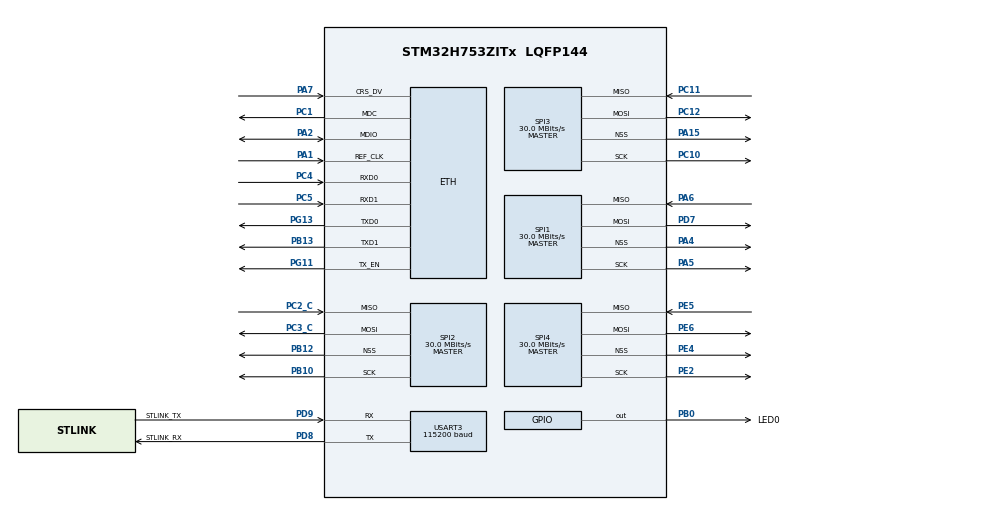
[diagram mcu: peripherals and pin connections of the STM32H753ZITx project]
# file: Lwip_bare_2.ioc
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CORTEX_M7.AccessPermission_S-Cortex_Memory_Protection_Unit_Region1_Settings_S=MPU_REGION_FULL_ACCESS
CORTEX_M7.AccessPermission_S-Cortex_Memory_Protection_Unit_Region2_Settings_S=MPU_REGION_FULL_ACCESS
CORTEX_M7.AccessPermission_Spec=MPU_REGION_NO_ACCESS
CORTEX_M7.BaseAddress_S-Cortex_Memory_Protection_Unit_Region1_Settings_S=0x30020000
CORTEX_M7.BaseAddress_S-Cortex_Memory_Protection_Unit_Region2_Settings_S=0x30040000
CORTEX_M7.BaseAddress_Spec=0x0
CORTEX_M7.CPU_DCache=Enabled
CORTEX_M7.CPU_ICache=Enabled
CORTEX_M7.DisableExec_S-Cortex_Memory_Protection_Unit_Region1_Settings_S=MPU_INSTRUCTION_ACCESS_DISABLE
CORTEX_M7.DisableExec_S-Cortex_Memory_Protection_Unit_Region2_Settings_S=MPU_INSTRUCTION_ACCESS_DISABLE
CORTEX_M7.DisableExec_Spec=MPU_INSTRUCTION_ACCESS_DISABLE
CORTEX_M7.Enable_S-Cortex_Memory_Protection_Unit_Region10_Settings_S=__NULL
CORTEX_M7.Enable_S-Cortex_Memory_Protection_Unit_Region11_Settings_S=__NULL
CORTEX_M7.Enable_S-Cortex_Memory_Protection_Unit_Region12_Settings_S=__NULL
CORTEX_M7.Enable_S-Cortex_Memory_Protection_Unit_Region13_Settings_S=__NULL
CORTEX_M7.Enable_S-Cortex_Memory_Protection_Unit_Region14_Settings_S=__NULL
CORTEX_M7.Enable_S-Cortex_Memory_Protection_Unit_Region15_Settings_S=__NULL
CORTEX_M7.Enable_S-Cortex_Memory_Protection_Unit_Region1_Settings_S=MPU_REGION_ENABLE
CORTEX_M7.Enable_S-Cortex_Memory_Protection_Unit_Region2_Settings_S=MPU_REGION_ENABLE
CORTEX_M7.Enable_S-Cortex_Memory_Protection_Unit_Region3_Settings_S=__NULL
CORTEX_M7.Enable_S-Cortex_Memory_Protection_Unit_Region4_Settings_S=__NULL
CORTEX_M7.Enable_S-Cortex_Memory_Protection_Unit_Region5_Settings_S=__NULL
CORTEX_M7.Enable_S-Cortex_Memory_Protection_Unit_Region6_Settings_S=__NULL
CORTEX_M7.Enable_S-Cortex_Memory_Protection_Unit_Region7_Settings_S=__NULL
CORTEX_M7.Enable_S-Cortex_Memory_Protection_Unit_Region8_Settings_S=__NULL
CORTEX_M7.Enable_S-Cortex_Memory_Protection_Unit_Region9_Settings_S=__NULL
CORTEX_M7.Enable_Spec=MPU_REGION_ENABLE
CORTEX_M7.IsBufferable_S-Cortex_Memory_Protection_Unit_Region1_Settings_S=MPU_ACCESS_NOT_BUFFERABLE
CORTEX_M7.IsBufferable_S-Cortex_Memory_Protection_Unit_Region2_Settings_S=MPU_ACCESS_BUFFERABLE
CORTEX_M7.IsBufferable_Spec=MPU_ACCESS_NOT_BUFFERABLE
CORTEX_M7.IsCacheable_S-Cortex_Memory_Protection_Unit_Region1_Settings_S=MPU_ACCESS_NOT_CACHEABLE
CORTEX_M7.IsCacheable_S-Cortex_Memory_Protection_Unit_Region2_Settings_S=MPU_ACCESS_NOT_CACHEABLE
CORTEX_M7.IsCacheable_Spec=MPU_ACCESS_NOT_CACHEABLE
CORTEX_M7.IsShareable_S-Cortex_Memory_Protection_Unit_Region1_Settings_S=MPU_ACCESS_NOT_SHAREABLE
CORTEX_M7.IsShareable_S-Cortex_Memory_Protection_Unit_Region2_Settings_S=MPU_ACCESS_SHAREABLE
CORTEX_M7.IsShareable_Spec=MPU_ACCESS_SHAREABLE
CORTEX_M7.MPU_Control=MPU_PRIVILEGED_DEFAULT
CORTEX_M7.Size_S-Cortex_Memory_Protection_Unit_Region1_Settings_S=MPU_REGION_SIZE_128KB
CORTEX_M7.Size_S-Cortex_Memory_Protection_Unit_Region2_Settings_S=MPU_REGION_SIZE_512B
CORTEX_M7.Size_Spec=MPU_REGION_SIZE_4GB
CORTEX_M7.SubRegionDisable_S-Cortex_Memory_Protection_Unit_Region1_Settings_S=0x0
CORTEX_M7.SubRegionDisable_S-Cortex_Memory_Protection_Unit_Region2_Settings_S=0x0
CORTEX_M7.SubRegionDisable_Spec=0x87
CORTEX_M7.TypeExtField_S-Cortex_Memory_Protection_Unit_Region1_Settings_S=MPU_TEX_LEVEL1
CORTEX_M7.TypeExtField_S-Cortex_Memory_Protection_Unit_Region2_Settings_S=MPU_TEX_LEVEL0
CORTEX_M7.TypeExtField_Spec=MPU_TEX_LEVEL0
CORTEX_M7.default_mode_Activation=1
Dma.Request0=SPI1_TX
Dma.Request1=SPI1_RX
Dma.Request2=SPI2_TX
Dma.Request3=SPI2_RX
Dma.Request4=SPI3_TX
Dma.Request5=SPI3_RX
Dma.Request6=SPI4_TX
Dma.Request7=SPI4_RX
Dma.SPI1_RX.1.Direction=DMA_PERIPH_TO_MEMORY
Dma.SPI1_RX.1.EventEnable=DISABLE
Dma.SPI1_RX.1.FIFOMode=DMA_FIFOMODE_ENABLE
Dma.SPI1_RX.1.FIFOThreshold=DMA_FIFO_THRESHOLD_FULL
Dma.SPI1_RX.1.Instance=DMA1_Stream1
Dma.SPI1_RX.1.MemBurst=DMA_MBURST_SINGLE
Dma.SPI1_RX.1.MemDataAlignment=DMA_MDATAALIGN_HALFWORD
Dma.SPI1_RX.1.MemInc=DMA_MINC_ENABLE
Dma.SPI1_RX.1.Mode=DMA_NORMAL
Dma.SPI1_RX.1.PeriphBurst=DMA_PBURST_SINGLE
Dma.SPI1_RX.1.PeriphDataAlignment=DMA_PDATAALIGN_HALFWORD
Dma.SPI1_RX.1.PeriphInc=DMA_PINC_DISABLE
Dma.SPI1_RX.1.Polarity=HAL_DMAMUX_REQ_GEN_RISING
Dma.SPI1_RX.1.Priority=DMA_PRIORITY_MEDIUM
Dma.SPI1_RX.1.RequestNumber=1
Dma.SPI1_RX.1.SignalID=NONE
Dma.SPI1_RX.1.SyncEnable=DISABLE
Dma.SPI1_RX.1.SyncPolarity=HAL_DMAMUX_SYNC_NO_EVENT
Dma.SPI1_RX.1.SyncRequestNumber=1
Dma.SPI1_RX.1.SyncSignalID=NONE
Dma.SPI1_TX.0.Direction=DMA_MEMORY_TO_PERIPH
Dma.SPI1_TX.0.EventEnable=DISABLE
Dma.SPI1_TX.0.FIFOMode=DMA_FIFOMODE_ENABLE
Dma.SPI1_TX.0.FIFOThreshold=DMA_FIFO_THRESHOLD_HALFFULL
Dma.SPI1_TX.0.Instance=DMA1_Stream0
Dma.SPI1_TX.0.MemBurst=DMA_MBURST_SINGLE
Dma.SPI1_TX.0.MemDataAlignment=DMA_MDATAALIGN_HALFWORD
Dma.SPI1_TX.0.MemInc=DMA_MINC_ENABLE
Dma.SPI1_TX.0.Mode=DMA_NORMAL
Dma.SPI1_TX.0.PeriphBurst=DMA_PBURST_SINGLE
Dma.SPI1_TX.0.PeriphDataAlignment=DMA_PDATAALIGN_HALFWORD
Dma.SPI1_TX.0.PeriphInc=DMA_PINC_DISABLE
Dma.SPI1_TX.0.Polarity=HAL_DMAMUX_REQ_GEN_RISING
Dma.SPI1_TX.0.Priority=DMA_PRIORITY_LOW
Dma.SPI1_TX.0.RequestNumber=1
Dma.SPI1_TX.0.SignalID=NONE
Dma.SPI1_TX.0.SyncEnable=DISABLE
Dma.SPI1_TX.0.SyncPolarity=HAL_DMAMUX_SYNC_NO_EVENT
Dma.SPI1_TX.0.SyncRequestNumber=1
Dma.SPI1_TX.0.SyncSignalID=NONE
Dma.SPI2_RX.3.Direction=DMA_PERIPH_TO_MEMORY
Dma.SPI2_RX.3.EventEnable=DISABLE
Dma.SPI2_RX.3.FIFOMode=DMA_FIFOMODE_DISABLE
Dma.SPI2_RX.3.Instance=DMA1_Stream3
Dma.SPI2_RX.3.MemDataAlignment=DMA_MDATAALIGN_HALFWORD
Dma.SPI2_RX.3.MemInc=DMA_MINC_ENABLE
Dma.SPI2_RX.3.Mode=DMA_NORMAL
Dma.SPI2_RX.3.PeriphDataAlignment=DMA_PDATAALIGN_HALFWORD
Dma.SPI2_RX.3.PeriphInc=DMA_PINC_DISABLE
Dma.SPI2_RX.3.Polarity=HAL_DMAMUX_REQ_GEN_RISING
Dma.SPI2_RX.3.Priority=DMA_PRIORITY_LOW
Dma.SPI2_RX.3.RequestNumber=1
Dma.SPI2_RX.3.SignalID=NONE
Dma.SPI2_RX.3.SyncEnable=DISABLE
Dma.SPI2_RX.3.SyncPolarity=HAL_DMAMUX_SYNC_NO_EVENT
Dma.SPI2_RX.3.SyncRequestNumber=1
Dma.SPI2_RX.3.SyncSignalID=NONE
Dma.SPI2_TX.2.Direction=DMA_MEMORY_TO_PERIPH
Dma.SPI2_TX.2.EventEnable=DISABLE
Dma.SPI2_TX.2.FIFOMode=DMA_FIFOMODE_ENABLE
Dma.SPI2_TX.2.FIFOThreshold=DMA_FIFO_THRESHOLD_FULL
Dma.SPI2_TX.2.Instance=DMA1_Stream2
Dma.SPI2_TX.2.MemBurst=DMA_MBURST_SINGLE
Dma.SPI2_TX.2.MemDataAlignment=DMA_MDATAALIGN_HALFWORD
Dma.SPI2_TX.2.MemInc=DMA_MINC_ENABLE
Dma.SPI2_TX.2.Mode=DMA_NORMAL
Dma.SPI2_TX.2.PeriphBurst=DMA_PBURST_SINGLE
Dma.SPI2_TX.2.PeriphDataAlignment=DMA_PDATAALIGN_HALFWORD
Dma.SPI2_TX.2.PeriphInc=DMA_PINC_DISABLE
Dma.SPI2_TX.2.Polarity=HAL_DMAMUX_REQ_GEN_RISING
Dma.SPI2_TX.2.Priority=DMA_PRIORITY_LOW
Dma.SPI2_TX.2.RequestNumber=1
Dma.SPI2_TX.2.SignalID=NONE
Dma.SPI2_TX.2.SyncEnable=DISABLE
Dma.SPI2_TX.2.SyncPolarity=HAL_DMAMUX_SYNC_NO_EVENT
Dma.SPI2_TX.2.SyncRequestNumber=1
Dma.SPI2_TX.2.SyncSignalID=NONE
Dma.SPI3_RX.5.Direction=DMA_PERIPH_TO_MEMORY
Dma.SPI3_RX.5.EventEnable=DISABLE
Dma.SPI3_RX.5.FIFOMode=DMA_FIFOMODE_ENABLE
Dma.SPI3_RX.5.FIFOThreshold=DMA_FIFO_THRESHOLD_FULL
Dma.SPI3_RX.5.Instance=DMA2_Stream1
Dma.SPI3_RX.5.MemBurst=DMA_MBURST_SINGLE
Dma.SPI3_RX.5.MemDataAlignment=DMA_MDATAALIGN_HALFWORD
Dma.SPI3_RX.5.MemInc=DMA_MINC_ENABLE
Dma.SPI3_RX.5.Mode=DMA_NORMAL
Dma.SPI3_RX.5.PeriphBurst=DMA_PBURST_SINGLE
Dma.SPI3_RX.5.PeriphDataAlignment=DMA_PDATAALIGN_HALFWORD
Dma.SPI3_RX.5.PeriphInc=DMA_PINC_DISABLE
Dma.SPI3_RX.5.Polarity=HAL_DMAMUX_REQ_GEN_RISING
Dma.SPI3_RX.5.Priority=DMA_PRIORITY_LOW
Dma.SPI3_RX.5.RequestNumber=1
Dma.SPI3_RX.5.SignalID=NONE
Dma.SPI3_RX.5.SyncEnable=DISABLE
Dma.SPI3_RX.5.SyncPolarity=HAL_DMAMUX_SYNC_NO_EVENT
Dma.SPI3_RX.5.SyncRequestNumber=1
Dma.SPI3_RX.5.SyncSignalID=NONE
Dma.SPI3_TX.4.Direction=DMA_MEMORY_TO_PERIPH
Dma.SPI3_TX.4.EventEnable=DISABLE
Dma.SPI3_TX.4.FIFOMode=DMA_FIFOMODE_ENABLE
Dma.SPI3_TX.4.FIFOThreshold=DMA_FIFO_THRESHOLD_FULL
Dma.SPI3_TX.4.Instance=DMA2_Stream0
Dma.SPI3_TX.4.MemBurst=DMA_MBURST_SINGLE
Dma.SPI3_TX.4.MemDataAlignment=DMA_MDATAALIGN_HALFWORD
Dma.SPI3_TX.4.MemInc=DMA_MINC_ENABLE
Dma.SPI3_TX.4.Mode=DMA_NORMAL
Dma.SPI3_TX.4.PeriphBurst=DMA_PBURST_SINGLE
Dma.SPI3_TX.4.PeriphDataAlignment=DMA_PDATAALIGN_HALFWORD
Dma.SPI3_TX.4.PeriphInc=DMA_PINC_DISABLE
Dma.SPI3_TX.4.Polarity=HAL_DMAMUX_REQ_GEN_RISING
Dma.SPI3_TX.4.Priority=DMA_PRIORITY_LOW
Dma.SPI3_TX.4.RequestNumber=1
Dma.SPI3_TX.4.SignalID=NONE
Dma.SPI3_TX.4.SyncEnable=DISABLE
Dma.SPI3_TX.4.SyncPolarity=HAL_DMAMUX_SYNC_NO_EVENT
Dma.SPI3_TX.4.SyncRequestNumber=1
Dma.SPI3_TX.4.SyncSignalID=NONE
Dma.SPI4_RX.7.Direction=DMA_PERIPH_TO_MEMORY
Dma.SPI4_RX.7.EventEnable=DISABLE
Dma.SPI4_RX.7.FIFOMode=DMA_FIFOMODE_ENABLE
Dma.SPI4_RX.7.FIFOThreshold=DMA_FIFO_THRESHOLD_FULL
Dma.SPI4_RX.7.Instance=DMA2_Stream3
Dma.SPI4_RX.7.MemBurst=DMA_MBURST_SINGLE
Dma.SPI4_RX.7.MemDataAlignment=DMA_MDATAALIGN_HALFWORD
Dma.SPI4_RX.7.MemInc=DMA_MINC_ENABLE
Dma.SPI4_RX.7.Mode=DMA_NORMAL
Dma.SPI4_RX.7.PeriphBurst=DMA_PBURST_SINGLE
Dma.SPI4_RX.7.PeriphDataAlignment=DMA_PDATAALIGN_HALFWORD
Dma.SPI4_RX.7.PeriphInc=DMA_PINC_DISABLE
Dma.SPI4_RX.7.Polarity=HAL_DMAMUX_REQ_GEN_RISING
Dma.SPI4_RX.7.Priority=DMA_PRIORITY_LOW
Dma.SPI4_RX.7.RequestNumber=1
Dma.SPI4_RX.7.SignalID=NONE
Dma.SPI4_RX.7.SyncEnable=DISABLE
Dma.SPI4_RX.7.SyncPolarity=HAL_DMAMUX_SYNC_NO_EVENT
Dma.SPI4_RX.7.SyncRequestNumber=1
Dma.SPI4_RX.7.SyncSignalID=NONE
Dma.SPI4_TX.6.Direction=DMA_MEMORY_TO_PERIPH
Dma.SPI4_TX.6.EventEnable=DISABLE
Dma.SPI4_TX.6.FIFOMode=DMA_FIFOMODE_ENABLE
Dma.SPI4_TX.6.FIFOThreshold=DMA_FIFO_THRESHOLD_FULL
Dma.SPI4_TX.6.Instance=DMA2_Stream2
Dma.SPI4_TX.6.MemBurst=DMA_MBURST_SINGLE
Dma.SPI4_TX.6.MemDataAlignment=DMA_MDATAALIGN_HALFWORD
Dma.SPI4_TX.6.MemInc=DMA_MINC_ENABLE
Dma.SPI4_TX.6.Mode=DMA_NORMAL
Dma.SPI4_TX.6.PeriphBurst=DMA_PBURST_SINGLE
Dma.SPI4_TX.6.PeriphDataAlignment=DMA_PDATAALIGN_HALFWORD
Dma.SPI4_TX.6.PeriphInc=DMA_PINC_DISABLE
Dma.SPI4_TX.6.Polarity=HAL_DMAMUX_REQ_GEN_RISING
Dma.SPI4_TX.6.Priority=DMA_PRIORITY_LOW
Dma.SPI4_TX.6.RequestNumber=1
Dma.SPI4_TX.6.SignalID=NONE
Dma.SPI4_TX.6.SyncEnable=DISABLE
Dma.SPI4_TX.6.SyncPolarity=HAL_DMAMUX_SYNC_NO_EVENT
Dma.SPI4_TX.6.SyncRequestNumber=1
Dma.SPI4_TX.6.SyncSignalID=NONE
ETH.ETH_RX_DESC_CNT=4
ETH.ETH_TX_DESC_CNT=4
ETH.MACAddr=00\:80\:E1\:00\:00\:00
ETH.MediaInterface=HAL_ETH_RMII_MODE
ETH.RxBuffLen=1536
ETH.RxBufferAddress=0x30040200
ETH.RxDescAddress=0x30040000
ETH.TxDescAddress=0x30040060
LWIP.API_LIB_DEBUG=LWIP_DBG_OFF
LWIP.API_MSG_DEBUG=LWIP_DBG_OFF
LWIP.ARP_MAXAGE=300
LWIP.ARP_QUEUEING=0
LWIP.ARP_QUEUE_LEN=3
LWIP.ARP_TABLE_SIZE=10
LWIP.AUTOIP_DEBUG=LWIP_DBG_OFF
LWIP.BSP.number=1
LWIP.CBCP_SUPPORT=0
LWIP.CCP_SUPPORT=0
LWIP.CHAP_DEFTIMEOUT=6
LWIP.CHAP_DEFTRANSMITS=10
LWIP.CHAP_SUPPORT=0
LWIP.CHECKSUM_BY_HARDWARE=1
LWIP.CHECKSUM_CHECK_ICMP=1
LWIP.CHECKSUM_CHECK_ICMP6=0
LWIP.CHECKSUM_CHECK_IP=0
LWIP.CHECKSUM_CHECK_TCP=0
LWIP.CHECKSUM_CHECK_UDP=0
LWIP.CHECKSUM_GEN_ICMP=1
LWIP.CHECKSUM_GEN_ICMP6=0
LWIP.CHECKSUM_GEN_IP=0
LWIP.CHECKSUM_GEN_TCP=0
LWIP.CHECKSUM_GEN_UDP=0
LWIP.CMSIS_VERSION-Enabled=1
LWIP.DEFAULT_ACCEPTMBOX_SIZE=6
LWIP.DEFAULT_RAW_RECVMBOX_SIZE=0
LWIP.DEFAULT_TCP_RECVMBOX_SIZE=6
LWIP.DEFAULT_THREAD_NAME="lwIP"
LWIP.DEFAULT_THREAD_PRIO=3
LWIP.DEFAULT_THREAD_STACKSIZE=1024
LWIP.DEFAULT_UDP_RECVMBOX_SIZE=6
LWIP.DEMAND_SUPPORT=0
LWIP.DHCP6_DEBUG=LWIP_DBG_OFF
LWIP.DHCP_DEBUG=LWIP_DBG_OFF
LWIP.DHCP_DOES_ARP_CHECK=1
LWIP.DNS_DEBUG=LWIP_DBG_OFF
LWIP.DNS_DOES_NAME_CHECK=1
LWIP.DNS_LOCAL_HOSTLIST=0
LWIP.DNS_LOCAL_HOSTLIST_IS_DYNAMIC=0
LWIP.DNS_MAX_NAME_LENGTH=256
LWIP.DNS_MAX_RETRIES=4
LWIP.DNS_MAX_SERVERS=2
LWIP.DNS_TABLE_SIZE=4
LWIP.EAP_DEFALLOWREQ=10
LWIP.EAP_DEFREQTIME=6
LWIP.EAP_SUPPORT=0
LWIP.ECP_SUPPORT=0
LWIP.ETHARP_DEBUG=LWIP_DBG_OFF
LWIP.ETHARP_STATS=0
LWIP.ETHARP_SUPPORT_STATIC_ENTRIES=0
LWIP.ETHARP_SUPPORT_VLAN=0
LWIP.ETHARP_TABLE_MATCH_NETIF=1
LWIP.ETH_PAD_SIZE=0
LWIP.ETH_RX_BUFFER_CNT=10
LWIP.FSM_DEFMAXCONFREQS=10
LWIP.FSM_DEFMAXNAKLOOPS=5
LWIP.FSM_DEFMAXTERMREQS=2
LWIP.FSM_DEFTIMEOUT=6
LWIP.HTTPD_DEBUG=LWIP_DBG_OFF
LWIP.HTTPD_DEBUG_TIMING=LWIP_DBG_OFF
LWIP.ICMP6_STATS=0
LWIP.ICMP_DEBUG=LWIP_DBG_OFF
LWIP.ICMP_STATS=0
LWIP.ICMP_TTL=255
LWIP.IGMP_DEBUG=LWIP_DBG_OFF
LWIP.IGMP_STATS=0
LWIP.INET_DEBUG=LWIP_DBG_OFF
LWIP.IP6_DEBUG=LWIP_DBG_OFF
LWIP.IP6_FRAG_STATS=0
LWIP.IP6_STATS=0
LWIP.IPFRAG_STATS=0
LWIP.IPV6_REASS_MAXAGE=60
LWIP.IP_ADDRESS=010.022.247.108
LWIP.IP_DEBUG=LWIP_DBG_OFF
LWIP.IP_DEFAULT_TTL=255
LWIP.IP_FORWARD=0
LWIP.IP_FORWARD_ALLOW_TX_ON_RX_NETIF=0
LWIP.IP_FRAG=1
LWIP.IP_OPTIONS_ALLOWED=1
LWIP.IP_REASSEMBLY=1
LWIP.IP_REASS_DEBUG=LWIP_DBG_OFF
LWIP.IP_REASS_MAXAGE=15
LWIP.IP_REASS_MAX_PBUFS=10
LWIP.IP_SOF_BROADCAST=0
LWIP.IP_SOF_BROADCAST_RECV=0
LWIP.IP_STATS=0
LWIP.LCP_DEFLOOPBACKFAIL=10
LWIP.LCP_ECHOINTERVAL=0
LWIP.LCP_MAXECHOFAILS=3
LWIP.LINK_STATS=0
LWIP.LQR_SUPPORT=0
LWIP.LWIP_ALLOW_MEM_FREE_FROM_OTHER_CONTEXT=0
LWIP.LWIP_ALTCP=0
LWIP.LWIP_ALTCP_TLS=0
LWIP.LWIP_ARP=1
LWIP.LWIP_AUTOIP=0
LWIP.LWIP_BROADCAST_PING=0
LWIP.LWIP_CALLBACK_API=1
LWIP.LWIP_CHECKSUM_CTRL_PER_NETIF=0
LWIP.LWIP_CHECKSUM_ON_COPY=0
LWIP.LWIP_COMPAT_SOCKETS=1
LWIP.LWIP_DBG_MIN_LEVEL=LWIP_DBG_LEVEL_ALL
LWIP.LWIP_DBG_TYPES_ON=LWIP_DBG_ON
LWIP.LWIP_DHCP=1
LWIP.LWIP_DHCP6_GET_NTP_SRV=0
LWIP.LWIP_DHCP6_MAX_DNS_SERVERS=2
LWIP.LWIP_DHCP6_MAX_NTP_SERVERS=1
LWIP.LWIP_DHCP_AUTOIP_COOP=0
LWIP.LWIP_DHCP_AUTOIP_COOP_TRIES=9
LWIP.LWIP_DHCP_BOOTP_FILE=0
LWIP.LWIP_DHCP_GET_NTP_SRV=0
LWIP.LWIP_DHCP_MAX_DNS_SERVERS=2
LWIP.LWIP_DHCP_MAX_NTP_SERVERS=1
LWIP.LWIP_DISABLE_MEMP_SANITY_CHECKS=0
LWIP.LWIP_DISABLE_TCP_SANITY_CHECKS=0
LWIP.LWIP_DNS=0
LWIP.LWIP_DNS_SECURE=7
LWIP.LWIP_DNS_SUPPORT_MDNS_QUERIES=0
LWIP.LWIP_ETHERNET=1
LWIP.LWIP_EVENT_API=0
LWIP.LWIP_HAVE_LOOPIF=0
LWIP.LWIP_HTTPD=0
LWIP.LWIP_ICMP=1
LWIP.LWIP_ICMP6=0
LWIP.LWIP_ICMP6_DATASIZE=8
LWIP.LWIP_ICMP6_HL=255
LWIP.LWIP_IGMP=0
LWIP.LWIP_INCLUDED_POLARSSL_ARC4=0
LWIP.LWIP_INCLUDED_POLARSSL_DES=0
LWIP.LWIP_INCLUDED_POLARSSL_MD4=0
LWIP.LWIP_INCLUDED_POLARSSL_MD5=0
LWIP.LWIP_INCLUDED_POLARSSL_SHA1=0
LWIP.LWIP_IPV4=1
LWIP.LWIP_IPV6=0
LWIP.LWIP_IPV6_ADDRESS_LIFETIMES=0
LWIP.LWIP_IPV6_AUTOCONFIG=0
LWIP.LWIP_IPV6_DHCP6=0
LWIP.LWIP_IPV6_DHCP6_STATEFUL=0
LWIP.LWIP_IPV6_DHCP6_STATELESS=0
LWIP.LWIP_IPV6_DUP_DETECT_ATTEMPTS=1
LWIP.LWIP_IPV6_FORWARD=0
LWIP.LWIP_IPV6_FRAG=1
LWIP.LWIP_IPV6_MLD=0
LWIP.LWIP_IPV6_NUM_ADDRESSES=3
LWIP.LWIP_IPV6_REASS=0
LWIP.LWIP_IPV6_SCOPES=0
LWIP.LWIP_IPV6_SCOPES_DEBUG=0
LWIP.LWIP_IPV6_SEND_ROUTER_SOLICIT=1
LWIP.LWIP_LOOPBACK_MAX_PBUFS=0
LWIP.LWIP_LOOPIF_MULTICAST=0
LWIP.LWIP_MDNS=0
LWIP.LWIP_MIB2_CALLBACKS=0
LWIP.LWIP_MPU_COMPATIBLE=0
LWIP.LWIP_MULTICAST_PING=0
LWIP.LWIP_MULTICAST_TX_OPTIONS=0
LWIP.LWIP_ND6_ALLOW_RA_UPDATES=1
LWIP.LWIP_ND6_DELAY_FIRST_PROBE_TIME=5000
LWIP.LWIP_ND6_MAX_ANYCAST_DELAY_TIME=1000
LWIP.LWIP_ND6_MAX_MULTICAST_SOLICIT=3
LWIP.LWIP_ND6_MAX_NEIGHBOR_ADVERTISEMENT=3
LWIP.LWIP_ND6_MAX_UNICAST_SOLICIT=3
LWIP.LWIP_ND6_NUM_DESTINATIONS=10
LWIP.LWIP_ND6_NUM_NEIGHBORS=10
LWIP.LWIP_ND6_NUM_PREFIXES=5
LWIP.LWIP_ND6_NUM_ROUTERS=3
LWIP.LWIP_ND6_QUEUEING=0
LWIP.LWIP_ND6_RDNSS_MAX_DNS_SERVERS=0
LWIP.LWIP_ND6_REACHABLE_TIME=30000
LWIP.LWIP_ND6_RETRANS_TIMER=1000
LWIP.LWIP_ND6_TCP_REACHABILITY_HINTS=1
LWIP.LWIP_NETBUF_RECVINFO=0
LWIP.LWIP_NETIF_API=0
LWIP.LWIP_NETIF_EXT_STATUS_CALLBACK=0
LWIP.LWIP_NETIF_HOSTNAME=0
LWIP.LWIP_NETIF_HWADDRHINT=0
LWIP.LWIP_NETIF_LINK_CALLBACK=1
LWIP.LWIP_NETIF_LOOPBACK=1
LWIP.LWIP_NETIF_LOOPBACK_MULTITHREADING=0
LWIP.LWIP_NETIF_REMOVE_CALLBACK=0
LWIP.LWIP_NETIF_STATUS_CALLBACK=0
LWIP.LWIP_NETIF_TX_SINGLE_PBUF=0
LWIP.LWIP_NUM_NETIF_CLIENT_DATA=0
LWIP.LWIP_PBUF_REF_T=u8_t
LWIP.LWIP_PERF=0
LWIP.LWIP_PPP_API=0
LWIP.LWIP_RAM_HEAP_POINTER=0x30020000
LWIP.LWIP_RAW=0
LWIP.LWIP_SINGLE_NETIF=0
LWIP.LWIP_SMTP=0
LWIP.LWIP_SNMP=0
LWIP.LWIP_SNMP_CONFIGURE_VERSIONS=0
LWIP.LWIP_SNMP_V3=0
LWIP.LWIP_SNMP_V3_CRYPTO=0
LWIP.LWIP_SNMP_V3_MBEDTLS=0
LWIP.LWIP_SNTP=0
LWIP.LWIP_SOCKET=0
LWIP.LWIP_SOCKET_OFFSET=0
LWIP.LWIP_STATS=0
LWIP.LWIP_STATS_DISPLAY=0
LWIP.LWIP_SUPPORT_CUSTOM_PBUF=1
LWIP.LWIP_TCP=1
LWIP.LWIP_TCPIP_CORE_LOCKING=0
LWIP.LWIP_TCPIP_CORE_LOCKING_INPUT=0
LWIP.LWIP_TCP_CLOSE_TIMEOUT_MS_DEFAULT=20000
LWIP.LWIP_TCP_MAX_SACK_NUM=4
LWIP.LWIP_TCP_PCB_NUM_EXT_ARGS=0
LWIP.LWIP_TCP_SACK_OUT=0
LWIP.LWIP_TCP_TIMESTAMPS=0
LWIP.LWIP_TESTMODE=0
LWIP.LWIP_TFTP=0
LWIP.LWIP_TIMERS=1
LWIP.LWIP_TIMERS_CUSTOM=0
LWIP.LWIP_UDP=1
LWIP.LWIP_UDPLITE=0
LWIP.LWIP_USE_EXTERNAL_MBEDTLS=0
LWIP.LWIP_USE_EXTERNAL_POLARSSL=0
LWIP.LWIP_WND_SCALE=0
LWIP.MAXNAMELEN=256
LWIP.MAXSECRETLEN=256
LWIP.MDNS_DEBUG=LWIP_DBG_OFF
LWIP.MEMP_DEBUG=LWIP_DBG_OFF
LWIP.MEMP_MEM_INIT=0
LWIP.MEMP_MEM_MALLOC=0
LWIP.MEMP_NUM_API_MSG=8
LWIP.MEMP_NUM_ARP_QUEUE=30
LWIP.MEMP_NUM_DNS_API_MSG=8
LWIP.MEMP_NUM_FRAG_PBUF=15
LWIP.MEMP_NUM_IGMP_GROUP=8
LWIP.MEMP_NUM_LOCALHOSTLIST=1
LWIP.MEMP_NUM_MLD6_GROUP=4
LWIP.MEMP_NUM_ND6_QUEUE=20
LWIP.MEMP_NUM_NETBUF=2
LWIP.MEMP_NUM_NETCONN=4
LWIP.MEMP_NUM_NETDB=1
LWIP.MEMP_NUM_NETIFAPI_MSG=8
LWIP.MEMP_NUM_PBUF=16
LWIP.MEMP_NUM_PPPOE_INTERFACES=1
LWIP.MEMP_NUM_PPPOL2TP_INTERFACES=1
LWIP.MEMP_NUM_PPPOS_INTERFACES=1
LWIP.MEMP_NUM_PPP_API_MSG=5
LWIP.MEMP_NUM_PPP_PCB=1
LWIP.MEMP_NUM_RAW_PCB=4
LWIP.MEMP_NUM_REASSDATA=5
LWIP.MEMP_NUM_SELECT_CB=4
LWIP.MEMP_NUM_SOCKET_SETGETSOCKOPT_DATA=8
LWIP.MEMP_NUM_SYS_TIMEOUT=5
LWIP.MEMP_NUM_TCPIP_MSG_API=8
LWIP.MEMP_NUM_TCPIP_MSG_INPKT=8
LWIP.MEMP_NUM_TCP_PCB=5
LWIP.MEMP_NUM_TCP_PCB_LISTEN=8
LWIP.MEMP_NUM_TCP_SEG=16
LWIP.MEMP_NUM_UDP_PCB=4
LWIP.MEMP_OVERFLOW_CHECK=0
LWIP.MEMP_SANITY_CHECK=0
LWIP.MEMP_STATS=0
LWIP.MEMP_USE_CUSTOM_POOLS=0
LWIP.MEM_ALIGNMENT=4
LWIP.MEM_DEBUG=LWIP_DBG_OFF
LWIP.MEM_LIBC_MALLOC=0
LWIP.MEM_OVERFLOW_CHECK=0
LWIP.MEM_SANITY_CHECK=0
LWIP.MEM_SIZE=16360
LWIP.MEM_STATS=0
LWIP.MEM_USE_POOLS=0
LWIP.MEM_USE_POOLS_TRY_BIGGER_POOL=0
LWIP.MIB2_STATS=0
LWIP.MLD6_STATS=0
LWIP.MPPE_SUPPORT=0
LWIP.MSCHAP_SUPPORT=0
LWIP.ND6_STATS=0
LWIP.NETIF_DEBUG=LWIP_DBG_OFF
LWIP.NETMASK_ADDRESS=255.255.255.000
LWIP.NO_SYS=1
LWIP.PAP_SUPPORT=0
LWIP.PBUF_DEBUG=LWIP_DBG_OFF
LWIP.PBUF_LINK_ENCAPSULATION_HLEN=0
LWIP.PBUF_LINK_HLEN=14
LWIP.PBUF_POOL_BUFSIZE=592
LWIP.PBUF_POOL_SIZE=16
LWIP.PPPOE_SUPPORT=0
LWIP.PPPOL2TP_AUTH_SUPPORT=0
LWIP.PPPOL2TP_SUPPORT=0
LWIP.PPPOS_SUPPORT=0
LWIP.PPP_DEBUG=LWIP_DBG_OFF
LWIP.PPP_DEFMRU=1500
LWIP.PPP_FCS_TABLE=1
LWIP.PPP_INPROC_IRQ_SAFE=0
LWIP.PPP_IPV4_SUPPORT=1
LWIP.PPP_IPV6_SUPPORT=0
LWIP.PPP_MAXIDLEFLAG=100
LWIP.PPP_MAXMRU=1500
LWIP.PPP_MD5_RANDM=0
LWIP.PPP_MINMRU=128
LWIP.PPP_MRU=1500
LWIP.PPP_NOTIFY_PHASE=0
LWIP.PPP_NUM_TIMEOUTS=0
LWIP.PPP_NUM_TIMEOUTS_PER_PCB=2
LWIP.PPP_SERVER=0
LWIP.PPP_SUPPORT=0
LWIP.PPP_USE_PBUF_RAM=0
LWIP.PRINTPKT_SUPPORT=0
LWIP.RAW_DEBUG=LWIP_DBG_OFF
LWIP.RAW_TTL=255
LWIP.RECV_BUFSIZE_DEFAULT=2000000000
LWIP.SLIPIF_THREAD_NAME="slipif_loop"
LWIP.SLIPIF_THREAD_PRIO=3
LWIP.SLIPIF_THREAD_STACKSIZE=1024
LWIP.SLIP_DEBUG=LWIP_DBG_OFF
LWIP.SMTP_DEBUG=LWIP_DBG_OFF
LWIP.SNMP_DEBUG=LWIP_DBG_OFF
LWIP.SNMP_LWIP_MIB2=0
LWIP.SNMP_MIB_DEBUG=LWIP_DBG_OFF
LWIP.SNMP_USE_NETCONN=0
LWIP.SNMP_USE_RAW=1
LWIP.SNTP_DEBUG=LWIP_DBG_OFF
LWIP.SOCKETS_DEBUG=LWIP_DBG_OFF
LWIP.SYS_DEBUG=LWIP_DBG_OFF
LWIP.SYS_LIGHTWEIGHT_PROT=0
LWIP.SYS_STATS=0
LWIP.TCPIP_DEBUG=LWIP_DBG_OFF
LWIP.TCPIP_MBOX_SIZE=6
LWIP.TCPIP_THREAD_NAME="tcpip_thread"
LWIP.TCPIP_THREAD_PRIO=24
LWIP.TCPIP_THREAD_STACKSIZE=1024
LWIP.TCP_CALCULATE_EFF_SEND_MSS=1
LWIP.TCP_CWND_DEBUG=LWIP_DBG_OFF
LWIP.TCP_DEBUG=LWIP_DBG_OFF
LWIP.TCP_DEFAULT_LISTEN_BACKLOG=255
LWIP.TCP_FR_DEBUG=LWIP_DBG_OFF
LWIP.TCP_INPUT_DEBUG=LWIP_DBG_OFF
LWIP.TCP_LISTEN_BACKLOG=0
LWIP.TCP_MAXRTX=12
LWIP.TCP_MSS=536
LWIP.TCP_OOSEQ_BYTES_LIMIT(pcb)=0
LWIP.TCP_OOSEQ_MAX_BYTES=0
LWIP.TCP_OOSEQ_MAX_PBUFS=0
LWIP.TCP_OOSEQ_PBUFS_LIMIT(pcb)=0
LWIP.TCP_OUTPUT_DEBUG=LWIP_DBG_OFF
LWIP.TCP_OVERSIZE=TCP_MSS
LWIP.TCP_QLEN_DEBUG=LWIP_DBG_OFF
LWIP.TCP_QUEUE_OOSEQ=1
LWIP.TCP_RCV_SCALE=0
LWIP.TCP_RST_DEBUG=LWIP_DBG_OFF
LWIP.TCP_RTO_DEBUG=LWIP_DBG_OFF
LWIP.TCP_SNDLOWAT=1071
LWIP.TCP_SNDQUEUELOWAT=5
LWIP.TCP_SND_BUF=1072
LWIP.TCP_SND_QUEUELEN=9
LWIP.TCP_STATS=0
LWIP.TCP_SYNMAXRTX=6
LWIP.TCP_TTL=255
LWIP.TCP_WND=2144
LWIP.TCP_WND_DEBUG=LWIP_DBG_OFF
LWIP.TCP_WND_UPDATE_THRESHOLD=536
LWIP.TFTP_DEBUG=LWIP_DBG_OFF
LWIP.TIMERS_DEBUG=LWIP_DBG_OFF
LWIP.UDP_DEBUG=LWIP_DBG_OFF
LWIP.UDP_STATS=0
LWIP.UDP_TTL=255
LWIP.UPAP_DEFREQTIME=30
LWIP.UPAP_DEFTIMEOUT=6
LWIP.UPAP_DEFTRANSMITS=10
LWIP.VJ_SUPPORT=0
LWIP.Version=v2.1.2_Cube
LWIP0.BSP.STBoard=false
LWIP0.BSP.api=BSP_COMPONENT_DRIVER
LWIP0.BSP.component=LAN8742
LWIP0.BSP.instance=LAN8742
LWIP0.BSP.name=Driver_PHY
LWIP0.BSP.semaphore=S_LAN8742
LWIP0.BSP.solution=LAN8742
Mcu.Family=STM32H7
Mcu.Name=STM32H753ZITx
Mcu.Package=LQFP144
NVIC.DMA1_Stream0_IRQn=true\:0\:0\:false\:false\:true\:false\:true\:true
NVIC.DMA1_Stream1_IRQn=true\:0\:0\:false\:false\:true\:false\:true\:true
NVIC.DMA1_Stream2_IRQn=true\:0\:0\:false\:false\:true\:false\:true\:true
NVIC.DMA1_Stream3_IRQn=true\:0\:0\:false\:false\:true\:false\:true\:true
NVIC.DMA2_Stream0_IRQn=true\:0\:0\:false\:false\:true\:false\:true\:true
NVIC.DMA2_Stream1_IRQn=true\:0\:0\:false\:false\:true\:false\:true\:true
NVIC.DMA2_Stream2_IRQn=true\:0\:0\:false\:false\:true\:false\:true\:true
NVIC.DMA2_Stream3_IRQn=true\:0\:0\:false\:false\:true\:false\:true\:true
NVIC.ETH_IRQn=true\:6\:0\:true\:false\:true\:true\:true\:true
NVIC.PriorityGroup=NVIC_PRIORITYGROUP_4
NVIC.SPI1_IRQn=true\:5\:0\:true\:false\:true\:true\:true\:true
NVIC.SPI2_IRQn=true\:4\:0\:true\:false\:true\:true\:true\:true
NVIC.SPI3_IRQn=true\:3\:0\:true\:false\:true\:false\:true\:true
NVIC.SPI4_IRQn=true\:2\:0\:true\:false\:true\:true\:true\:true
NVIC.TIM2_IRQn=true\:10\:0\:true\:false\:true\:true\:true\:true
NVIC.TIM6_DAC_IRQn=true\:15\:0\:false\:false\:true\:false\:true\:true
NVIC.TimeBase=TIM6_DAC_IRQn
NVIC.TimeBaseIP=TIM6
PA1.GPIO_Speed_Default_HIGH=GPIO_SPEED_FREQ_VERY_HIGH
PA1.Mode=RMII
PA1.Signal=ETH_REF_CLK
PA15\ (JTDI).GPIO_Speed=GPIO_SPEED_FREQ_MEDIUM
PA15\ (JTDI).Mode=NSS_Signal_Hard_Output
PA15\ (JTDI).Signal=SPI3_NSS
PA2.GPIO_Speed_Default_HIGH=GPIO_SPEED_FREQ_VERY_HIGH
PA2.Mode=RMII
PA2.Signal=ETH_MDIO
PA4.GPIO_Speed=GPIO_SPEED_FREQ_MEDIUM
PA4.Mode=NSS_Signal_Hard_Output
PA4.Signal=SPI1_NSS
PA5.GPIO_Speed=GPIO_SPEED_FREQ_MEDIUM
PA5.Mode=Full_Duplex_Master
PA5.Signal=SPI1_SCK
PA6.GPIO_Speed=GPIO_SPEED_FREQ_MEDIUM
PA6.Mode=Full_Duplex_Master
PA6.Signal=SPI1_MISO
PA7.GPIO_Speed_Default_HIGH=GPIO_SPEED_FREQ_VERY_HIGH
PA7.Mode=RMII
PA7.Signal=ETH_CRS_DV
PB0.GPIO_Label=LED0
PB0.Signal=GPIO_Output
PB10.GPIO_Speed=GPIO_SPEED_FREQ_MEDIUM
PB10.Mode=Full_Duplex_Master
PB10.Signal=SPI2_SCK
PB12.GPIO_Speed=GPIO_SPEED_FREQ_MEDIUM
PB12.Mode=NSS_Signal_Hard_Output
PB12.Signal=SPI2_NSS
PB13.GPIO_Speed_Default_HIGH=GPIO_SPEED_FREQ_VERY_HIGH
PB13.Mode=RMII
PB13.Signal=ETH_TXD1
PC1.GPIO_Speed_Default_HIGH=GPIO_SPEED_FREQ_VERY_HIGH
PC1.Mode=RMII
PC1.Signal=ETH_MDC
PC10.GPIO_Speed=GPIO_SPEED_FREQ_MEDIUM
PC10.Mode=Full_Duplex_Master
PC10.Signal=SPI3_SCK
PC11.GPIO_Speed=GPIO_SPEED_FREQ_MEDIUM
PC11.Mode=Full_Duplex_Master
PC11.Signal=SPI3_MISO
PC12.GPIO_Speed=GPIO_SPEED_FREQ_MEDIUM
PC12.Mode=Full_Duplex_Master
PC12.Signal=SPI3_MOSI
PC14-OSC32_IN\ (OSC32_IN).Signal=RCC_OSC32_IN
PC15-OSC32_OUT\ (OSC32_OUT).Signal=RCC_OSC32_OUT
PC2_C.GPIO_Speed=GPIO_SPEED_FREQ_MEDIUM
PC2_C.Mode=Full_Duplex_Master
PC2_C.Signal=SPI2_MISO
PC3_C.GPIO_Speed=GPIO_SPEED_FREQ_MEDIUM
PC3_C.Mode=Full_Duplex_Master
PC3_C.Signal=SPI2_MOSI
PC4.GPIO_Speed_Default_HIGH=GPIO_SPEED_FREQ_VERY_HIGH
PC4.Mode=RMII
PC4.Signal=ETH_RXD0
PC5.GPIO_Speed_Default_HIGH=GPIO_SPEED_FREQ_VERY_HIGH
PC5.Mode=RMII
PC5.Signal=ETH_RXD1
PD7.GPIO_Speed=GPIO_SPEED_FREQ_MEDIUM
PD7.Mode=Full_Duplex_Master
PD7.Signal=SPI1_MOSI
PD8.GPIO_Label=STLINK_RX
PD8.Mode=Asynchronous
PD8.Signal=USART3_TX
PD9.GPIO_Label=STLINK_TX
PD9.Mode=Asynchronous
PD9.Signal=USART3_RX
PE2.GPIO_Speed=GPIO_SPEED_FREQ_MEDIUM
PE2.Mode=Full_Duplex_Master
PE2.Signal=SPI4_SCK
PE4.GPIO_Speed=GPIO_SPEED_FREQ_MEDIUM
PE4.Mode=NSS_Signal_Hard_Output
PE4.Signal=SPI4_NSS
PE5.GPIO_Speed=GPIO_SPEED_FREQ_MEDIUM
PE5.Mode=Full_Duplex_Master
PE5.Signal=SPI4_MISO
PE6.GPIO_Speed=GPIO_SPEED_FREQ_MEDIUM
PE6.Mode=Full_Duplex_Master
PE6.Signal=SPI4_MOSI
PG11.GPIO_Speed_Default_HIGH=GPIO_SPEED_FREQ_VERY_HIGH
PG11.Mode=RMII
PG11.Signal=ETH_TX_EN
PG13.GPIO_Speed_Default_HIGH=GPIO_SPEED_FREQ_VERY_HIGH
PG13.Mode=RMII
PG13.Signal=ETH_TXD0
PH0-OSC_IN\ (PH0).Mode=HSE-External-Clock-Source
PH0-OSC_IN\ (PH0).Signal=RCC_OSC_IN
PH1-OSC_OUT\ (PH1).Signal=RCC_OSC_OUT
ProjectManager.HeapSize=0x400
ProjectManager.StackSize=0x2000
ProjectManager.TargetToolchain=STM32CubeIDE
RCC.ADCFreq_Value=240000000
RCC.APB1Freq_Value=120000000
RCC.APB2Freq_Value=120000000
RCC.APB3Freq_Value=120000000
RCC.APB4Freq_Value=120000000
RCC.CortexFreq_Value=240000000
RCC.D1PPRE=RCC_APB3_DIV2
RCC.D2PPRE1=RCC_APB1_DIV2
RCC.D2PPRE2=RCC_APB2_DIV2
RCC.D3PPRE=RCC_APB4_DIV2
RCC.DIVM1=4
RCC.DIVM2=4
RCC.DIVN1=30
RCC.DIVN2=30
RCC.DIVQ1=4
RCC.DIVQ2=4
RCC.FLatency=FLASH_LATENCY_4
RCC.HCLKFreq_Value=240000000
RCC.PLLFRACN=0
RCC.PWR_Regulator_Voltage_Scale=PWR_REGULATOR_VOLTAGE_SCALE0
RCC.SYSCLKFreq_VALUE=240000000
RCC.SYSCLKSource=RCC_SYSCLKSOURCE_PLLCLK
RCC.Spi45ClockSelection=RCC_SPI45CLKSOURCE_PLL2
RCC.USBFreq_Value=120000000
SPI1.BaudRatePrescaler=SPI_BAUDRATEPRESCALER_4
SPI1.CLKPhase=SPI_PHASE_1EDGE
SPI1.CLKPolarity=SPI_POLARITY_LOW
SPI1.CRCCalculation=SPI_CRCCALCULATION_DISABLE
SPI1.CalculateBaudRate=30.0 MBits/s
SPI1.DataSize=SPI_DATASIZE_16BIT
SPI1.Direction=SPI_DIRECTION_2LINES
SPI1.FifoThreshold=SPI_FIFO_THRESHOLD_04DATA
SPI1.FirstBit=SPI_FIRSTBIT_MSB
SPI1.IOSwap=SPI_IO_SWAP_DISABLE
SPI1.MasterInterDataIdleness=SPI_MASTER_INTERDATA_IDLENESS_00CYCLE
SPI1.MasterKeepIOState=SPI_MASTER_KEEP_IO_STATE_DISABLE
SPI1.MasterReceiverAutoSusp=SPI_MASTER_RX_AUTOSUSP_DISABLE
SPI1.MasterSSIdleness=SPI_MASTER_SS_IDLENESS_00CYCLE
SPI1.Mode=SPI_MODE_MASTER
SPI1.NSS=SPI_NSS_HARD_OUTPUT
SPI1.NSSPMode=SPI_NSS_PULSE_ENABLE
SPI1.NSSPolarity=SPI_NSS_POLARITY_LOW
SPI1.RxCRCInitializationPattern=SPI_CRC_INITIALIZATION_ALL_ZERO_PATTERN
SPI1.TIMode=SPI_TIMODE_DISABLE
SPI1.TxCRCInitializationPattern=SPI_CRC_INITIALIZATION_ALL_ZERO_PATTERN
SPI1.VirtualNSS=VM_NSSHARD
SPI1.VirtualType=VM_MASTER
SPI2.BaudRatePrescaler=SPI_BAUDRATEPRESCALER_4
SPI2.CalculateBaudRate=30.0 MBits/s
SPI2.DataSize=SPI_DATASIZE_16BIT
SPI2.Direction=SPI_DIRECTION_2LINES
SPI2.FifoThreshold=SPI_FIFO_THRESHOLD_02DATA
SPI2.Mode=SPI_MODE_MASTER
SPI2.VirtualNSS=VM_NSSHARD
SPI2.VirtualType=VM_MASTER
SPI3.BaudRatePrescaler=SPI_BAUDRATEPRESCALER_4
SPI3.CalculateBaudRate=30.0 MBits/s
SPI3.DataSize=SPI_DATASIZE_16BIT
SPI3.Direction=SPI_DIRECTION_2LINES
SPI3.Mode=SPI_MODE_MASTER
SPI3.VirtualNSS=VM_NSSHARD
SPI3.VirtualType=VM_MASTER
SPI4.BaudRatePrescaler=SPI_BAUDRATEPRESCALER_4
SPI4.CalculateBaudRate=30.0 MBits/s
SPI4.DataSize=SPI_DATASIZE_16BIT
SPI4.Direction=SPI_DIRECTION_2LINES
SPI4.Mode=SPI_MODE_MASTER
SPI4.VirtualNSS=VM_NSSHARD
SPI4.VirtualType=VM_MASTER
TIM2.Period=240000-1
USART3.AutoBaudRateEnableParam=UART_ADVFEATURE_AUTOBAUDRATE_DISABLE
USART3.BaudRate=115200
USART3.ClockPrescaler=PRESCALER_DIV1
USART3.DMADisableonRxErrorParam=ADVFEATURE_DMA_ENABLEONRXERROR
USART3.DataInvertParam=ADVFEATURE_DATAINV_DISABLE
USART3.FIFOMode=FIFOMODE_DISABLE
USART3.MSBFirstParam=ADVFEATURE_MSBFIRST_DISABLE
USART3.Mode=MODE_TX_RX
USART3.OneBitSampling=UART_ONE_BIT_SAMPLE_DISABLE
USART3.OverSampling=UART_OVERSAMPLING_16
USART3.OverrunDisableParam=ADVFEATURE_OVERRUN_ENABLE
USART3.Parity=PARITY_NONE
USART3.RXFIFOThreshold=RXFIFO_THRESHOLD_1EIGHTHFULL
USART3.RxPinLevelInvertParam=ADVFEATURE_RXINV_DISABLE
USART3.StopBits=STOPBITS_1
USART3.SwapParam=ADVFEATURE_SWAP_DISABLE
USART3.TXFIFOThreshold=TXFIFO_THRESHOLD_1EIGHTHFULL
USART3.TxPinLevelInvertParam=ADVFEATURE_TXINV_DISABLE
USART3.VirtualMode-Asynchronous=VM_ASYNC
USART3.WordLength=WORDLENGTH_8B
VP_LWIP_VS_Enabled.Mode=Enabled
VP_MEMORYMAP_VS_MEMORYMAP.Mode=CurAppReg
VP_SYS_VS_tim6.Mode=TIM6
VP_TIM2_VS_ClockSourceINT.Mode=Internal
board=NUCLEO-H753ZI

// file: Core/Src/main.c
/* USER CODE BEGIN Header */
/**
 ******************************************************************************
 * @file           : main.c
 * @brief          : Main program body
 ******************************************************************************
 * @attention
 *
 * Copyright (c) 2026 STMicroelectronics.
 * All rights reserved.
 *
 * This software is licensed under terms that can be found in the LICENSE file
 * in the root directory of this software component.
 * If no LICENSE file comes with this software, it is provided AS-IS.
 *
 ******************************************************************************
 */
/* USER CODE END Header */
#include "main.h"
#include "lwip.h"

/* USER CODE BEGIN Includes */
#include<string.h>
#include <inttypes.h>
#include "print3.h"

/* USER CODE END Includes */

/* USER CODE BEGIN PD */
#define UDP_BUFFER_SIZE 512 //bytes
#define SPI_BUFFER_SIZE_BYTES 64 // keep 32 bit alignment
#define SPI_BUFFER_SIZE_WORDS 32 // to keep 32 bit alignment
#define NUM_ACTUATORS 26 //

/* USER CODE END PD */

TIM_HandleTypeDef htim2;

UART_HandleTypeDef huart3;

/* USER CODE BEGIN PV */

typedef struct {
    uint32_t ms;
    uint32_t us;
} split_time_t;

extern struct netif gnetif;

union udp_data {
	uint8_t bytes[UDP_BUFFER_SIZE];
	int16_t values[UDP_BUFFER_SIZE / 2];
};

union udp_data udp_rx;
uint8_t spi_buffer_length_bytes = SPI_BUFFER_SIZE_BYTES;
uint16_t test_val={0};

/* SPI buffers */
// Use compiler attributes to align to 32 bytes and pad the size to a multiple of 32

__attribute__((section(".dma_buffer"), used, aligned(32)))   uint16_t spi1_tx_buffer[SPI_BUFFER_SIZE_WORDS]; // 64 bytes
__attribute__((section(".dma_buffer"), used, aligned(32)))   uint16_t spi1_rx_buffer[SPI_BUFFER_SIZE_WORDS]; // 64 bytes
__attribute__((section(".dma_buffer"), used, aligned(32)))   uint16_t spi2_tx_buffer[SPI_BUFFER_SIZE_WORDS]; // 64 bytes
__attribute__((section(".dma_buffer"), used, aligned(32)))   uint16_t spi2_rx_buffer[SPI_BUFFER_SIZE_WORDS]; // 64 bytes
__attribute__((section(".dma_buffer"), used, aligned(32)))   uint16_t spi3_tx_buffer[SPI_BUFFER_SIZE_WORDS]; // 64 bytes
__attribute__((section(".dma_buffer"), used, aligned(32)))   uint16_t spi3_rx_buffer[SPI_BUFFER_SIZE_WORDS]; // 64 bytes
__attribute__((section(".dma_buffer"), used, aligned(32)))   uint16_t spi4_tx_buffer[SPI_BUFFER_SIZE_WORDS]; // 64 bytes
__attribute__((section(".dma_buffer"), used, aligned(32)))   uint16_t spi4_rx_buffer[SPI_BUFFER_SIZE_WORDS]; // 64 bytes

volatile uint8_t spi_txfer_complete = 0; // All DMA SPI transfers are complete
volatile uint8_t spi_data_ready = 0; // flag to indicate SPI data is ready for processing

volatile uint32_t sys_time_ms = {0};
volatile split_time_t sys_time = {0};
volatile split_time_t start_time = {0};
volatile split_time_t end_time = {0};

ip_addr_t client_addr;  // Address of sender; client_addr.addr is the actual value.
uint16_t client_port;

/* USER CODE END PV */

void SystemClock_Config(void);
static void MPU_Config(void);
static void MX_GPIO_Init(void);
static void MX_DMA_Init(void);
static void MX_SPI1_Init(void);
static void MX_USART3_UART_Init(void);
static void MX_TIM2_Init(void);
static void MX_SPI2_Init(void);
static void MX_SPI3_Init(void);
static void MX_SPI4_Init(void);
/* USER CODE BEGIN PFP */
void DWT_Init(void);
void update_stats(uint32_t val);
void SPI1_DMA_txfer(void);
void SPI2_DMA_txfer(void);
void SPI3_DMA_txfer(void);
void SPI4_DMA_txfer(void);
void udp_receive_callback(void *arg, // User argument - udp_recv `arg` parameter
		struct udp_pcb *upcb,   // Receiving Protocol Control Block
		struct pbuf *p,         // Pointer to Datagram
		const ip_addr_t *addr,  // Address of sender
		u16_t port);

split_time_t get_sys_time(void);

//HAL_StatusTypeDef print_uart3(const char *pData);

/* USER CODE END PFP */

int main(void)
{

  /* MPU Configuration--------------------------------------------------------*/
  MPU_Config();

  /* Enable the CPU Cache */

  /* Enable I-Cache---------------------------------------------------------*/
  SCB_EnableICache();

  /* Enable D-Cache---------------------------------------------------------*/
  SCB_EnableDCache();

  /* MCU Configuration--------------------------------------------------------*/

  /* Reset of all peripherals, Initializes the Flash interface and the Systick. */
  HAL_Init();

  /* Configure the system clock */
  SystemClock_Config();

  /* Initialize all configured peripherals */
  MX_GPIO_Init();
  MX_DMA_Init();
  MX_LWIP_Init();
  MX_SPI1_Init();
  MX_USART3_UART_Init();
  MX_TIM2_Init();
  MX_SPI2_Init();
  MX_SPI3_Init();
  MX_SPI4_Init();
  /* USER CODE BEGIN 2 */
  DWT_Init();

	HAL_TIM_Base_Start_IT(&htim2);
	memset(&spi1_tx_buffer, 0, sizeof(spi1_tx_buffer));
	memset(&spi1_rx_buffer, 0, sizeof(spi1_rx_buffer));
	memset(&spi2_tx_buffer, 0, sizeof(spi2_tx_buffer));
	memset(&spi2_rx_buffer, 0, sizeof(spi2_rx_buffer));
	memset(&spi3_tx_buffer, 0, sizeof(spi3_tx_buffer));
	memset(&spi3_rx_buffer, 0, sizeof(spi3_rx_buffer));
	memset(&spi4_tx_buffer, 0, sizeof(spi4_tx_buffer));
	memset(&spi4_rx_buffer, 0, sizeof(spi4_rx_buffer));

	char msg[1024] = { 0 };

	print_uart3("Starting KASM Interface\r\n");

	/*wait for IP address to be assigned. DHCP can take a few seconds*/

	char no_ip[] = "0.0.0.0";

	print_uart3("Waiting for IP address to be assigned\r\n");

	while (strcmp(no_ip, ip4addr_ntoa(netif_ip4_addr(&gnetif))) == 0) {
		MX_LWIP_Process();
	}

	/* Determine IP address */
	sprintf(msg, "IP address: %s\r\n", ip4addr_ntoa(netif_ip4_addr(&gnetif)));
	print_uart3(msg);
	sprintf(msg, "Netmask: %s\r\n", ip4addr_ntoa(netif_ip4_netmask(&gnetif)));
	print_uart3(msg);
	sprintf(msg, "Gateway: %s\r\n", ip4addr_ntoa(netif_ip4_gw(&gnetif)));
	print_uart3(msg);

	u16_t port = 5001; // port to listen from

	struct udp_pcb *my_udp = udp_new();

	udp_bind(my_udp, IP_ADDR_ANY, port);
	udp_recv(my_udp, udp_receive_callback, NULL);
	if (((uint32_t) spi1_tx_buffer & 0xFF000000) != 0x30000000) {
		sprintf(msg, "Buffer not in RAM D2: %lu\r\n",
				(uint32_t) spi1_tx_buffer);
		print_uart3(msg);
	}

  /* USER CODE END 2 */

  /* Infinite loop */
  /* USER CODE BEGIN WHILE */
	while (1) {
		MX_LWIP_Process();

		if (spi_data_ready == 1) {

			SPI1_DMA_txfer(); // initiate SPI transfers DMA version
			SPI2_DMA_txfer();
			SPI3_DMA_txfer();
			SPI4_DMA_txfer();
			spi_data_ready = 0;
		}
		if (spi_txfer_complete == 1) {
			char msg[100];
			end_time = get_sys_time();

//			int len = sprintf(msg, "%d,%lu.%03lu,%lu.%03lu",test_val, start_time.ms, start_time.us, end_time.ms, end_time.us);
			int len = sprintf(msg, "%d,%lu,%lu", test_val, (uint32_t)0, (uint32_t) TIM2->CNT);

			struct pbuf *udp_buffer = pbuf_alloc(PBUF_TRANSPORT, len, PBUF_RAM);
			if (udp_buffer != NULL) {
				memcpy(udp_buffer->payload, msg, len);

				// Pass the ADDRESS of our stored ip_addr_t
				udp_sendto(my_udp, udp_buffer, &client_addr, client_port);

				pbuf_free(udp_buffer);
			}

			spi_txfer_complete = 0;
		}

		/* USER CODE END WHILE */

	}
}

void SystemClock_Config(void)
{
  RCC_OscInitTypeDef RCC_OscInitStruct = {0};
  RCC_ClkInitTypeDef RCC_ClkInitStruct = {0};

  /** Supply configuration update enable
  */
  HAL_PWREx_ConfigSupply(PWR_LDO_SUPPLY);

  /** Configure the main internal regulator output voltage
  */
  __HAL_PWR_VOLTAGESCALING_CONFIG(PWR_REGULATOR_VOLTAGE_SCALE0);

  while(!__HAL_PWR_GET_FLAG(PWR_FLAG_VOSRDY)) {}

  /** Initializes the RCC Oscillators according to the specified parameters
  * in the RCC_OscInitTypeDef structure.
  */
  RCC_OscInitStruct.OscillatorType = RCC_OSCILLATORTYPE_HSI;
  RCC_OscInitStruct.HSIState = RCC_HSI_DIV1;
  RCC_OscInitStruct.HSICalibrationValue = RCC_HSICALIBRATION_DEFAULT;
  RCC_OscInitStruct.PLL.PLLState = RCC_PLL_ON;
  RCC_OscInitStruct.PLL.PLLSource = RCC_PLLSOURCE_HSI;
  RCC_OscInitStruct.PLL.PLLM = 4;
  RCC_OscInitStruct.PLL.PLLN = 30;
  RCC_OscInitStruct.PLL.PLLP = 2;
  RCC_OscInitStruct.PLL.PLLQ = 4;
  RCC_OscInitStruct.PLL.PLLR = 2;
  RCC_OscInitStruct.PLL.PLLRGE = RCC_PLL1VCIRANGE_3;
  RCC_OscInitStruct.PLL.PLLVCOSEL = RCC_PLL1VCOWIDE;
  RCC_OscInitStruct.PLL.PLLFRACN = 0;
  if (HAL_RCC_OscConfig(&RCC_OscInitStruct) != HAL_OK)
  {
    Error_Handler();
  }

  /** Initializes the CPU, AHB and APB buses clocks
  */
  RCC_ClkInitStruct.ClockType = RCC_CLOCKTYPE_HCLK|RCC_CLOCKTYPE_SYSCLK
                              |RCC_CLOCKTYPE_PCLK1|RCC_CLOCKTYPE_PCLK2
                              |RCC_CLOCKTYPE_D3PCLK1|RCC_CLOCKTYPE_D1PCLK1;
  RCC_ClkInitStruct.SYSCLKSource = RCC_SYSCLKSOURCE_PLLCLK;
  RCC_ClkInitStruct.SYSCLKDivider = RCC_SYSCLK_DIV1;
  RCC_ClkInitStruct.AHBCLKDivider = RCC_HCLK_DIV1;
  RCC_ClkInitStruct.APB3CLKDivider = RCC_APB3_DIV2;
  RCC_ClkInitStruct.APB1CLKDivider = RCC_APB1_DIV2;
  RCC_ClkInitStruct.APB2CLKDivider = RCC_APB2_DIV2;
  RCC_ClkInitStruct.APB4CLKDivider = RCC_APB4_DIV2;

  if (HAL_RCC_ClockConfig(&RCC_ClkInitStruct, FLASH_LATENCY_4) != HAL_OK)
  {
    Error_Handler();
  }
}

static void MX_SPI1_Init(void)
{

  /* USER CODE BEGIN SPI1_Init 0 */
	LL_DMA_ConfigAddresses(DMA1, LL_DMA_STREAM_0, (uint32_t) spi1_tx_buffer,
			(uint32_t) &(SPI1->TXDR), LL_DMA_DIRECTION_MEMORY_TO_PERIPH);
	LL_DMA_ConfigAddresses(DMA1, LL_DMA_STREAM_1, (uint32_t) &(SPI1->RXDR),
			(uint32_t) spi1_rx_buffer, LL_DMA_DIRECTION_PERIPH_TO_MEMORY);

  /* USER CODE END SPI1_Init 0 */

  LL_SPI_InitTypeDef SPI_InitStruct = {0};

  LL_GPIO_InitTypeDef GPIO_InitStruct = {0};
  RCC_PeriphCLKInitTypeDef PeriphClkInitStruct = {0};

  /** Initializes the peripherals clock
  */
  PeriphClkInitStruct.PeriphClockSelection = RCC_PERIPHCLK_SPI1;
  PeriphClkInitStruct.Spi123ClockSelection = RCC_SPI123CLKSOURCE_PLL;
  if (HAL_RCCEx_PeriphCLKConfig(&PeriphClkInitStruct) != HAL_OK)
  {
    Error_Handler();
  }

  /* Peripheral clock enable */
  LL_APB2_GRP1_EnableClock(LL_APB2_GRP1_PERIPH_SPI1);

  LL_AHB4_GRP1_EnableClock(LL_AHB4_GRP1_PERIPH_GPIOA);
  LL_AHB4_GRP1_EnableClock(LL_AHB4_GRP1_PERIPH_GPIOD);
  /**SPI1 GPIO Configuration
  PA4   ------> SPI1_NSS
  PA5   ------> SPI1_SCK
  PA6   ------> SPI1_MISO
  PD7   ------> SPI1_MOSI
  */
  GPIO_InitStruct.Pin = LL_GPIO_PIN_4|LL_GPIO_PIN_5|LL_GPIO_PIN_6;
  GPIO_InitStruct.Mode = LL_GPIO_MODE_ALTERNATE;
  GPIO_InitStruct.Speed = LL_GPIO_SPEED_FREQ_MEDIUM;
  GPIO_InitStruct.OutputType = LL_GPIO_OUTPUT_PUSHPULL;
  GPIO_InitStruct.Pull = LL_GPIO_PULL_NO;
  GPIO_InitStruct.Alternate = LL_GPIO_AF_5;
  LL_GPIO_Init(GPIOA, &GPIO_InitStruct);

  GPIO_InitStruct.Pin = LL_GPIO_PIN_7;
  GPIO_InitStruct.Mode = LL_GPIO_MODE_ALTERNATE;
  GPIO_InitStruct.Speed = LL_GPIO_SPEED_FREQ_MEDIUM;
  GPIO_InitStruct.OutputType = LL_GPIO_OUTPUT_PUSHPULL;
  GPIO_InitStruct.Pull = LL_GPIO_PULL_NO;
  GPIO_InitStruct.Alternate = LL_GPIO_AF_5;
  LL_GPIO_Init(GPIOD, &GPIO_InitStruct);

  /* SPI1 DMA Init */

  /* SPI1_TX Init */
  LL_DMA_SetPeriphRequest(DMA1, LL_DMA_STREAM_0, LL_DMAMUX1_REQ_SPI1_TX);

  LL_DMA_SetDataTransferDirection(DMA1, LL_DMA_STREAM_0, LL_DMA_DIRECTION_MEMORY_TO_PERIPH);

  LL_DMA_SetStreamPriorityLevel(DMA1, LL_DMA_STREAM_0, LL_DMA_PRIORITY_LOW);

  LL_DMA_SetMode(DMA1, LL_DMA_STREAM_0, LL_DMA_MODE_NORMAL);

  LL_DMA_SetPeriphIncMode(DMA1, LL_DMA_STREAM_0, LL_DMA_PERIPH_NOINCREMENT);

  LL_DMA_SetMemoryIncMode(DMA1, LL_DMA_STREAM_0, LL_DMA_MEMORY_INCREMENT);

  LL_DMA_SetPeriphSize(DMA1, LL_DMA_STREAM_0, LL_DMA_PDATAALIGN_HALFWORD);

  LL_DMA_SetMemorySize(DMA1, LL_DMA_STREAM_0, LL_DMA_MDATAALIGN_HALFWORD);

  LL_DMA_EnableFifoMode(DMA1, LL_DMA_STREAM_0);

  LL_DMA_SetFIFOThreshold(DMA1, LL_DMA_STREAM_0, LL_DMA_FIFOTHRESHOLD_1_2);

  LL_DMA_SetMemoryBurstxfer(DMA1, LL_DMA_STREAM_0, LL_DMA_MBURST_SINGLE);

  LL_DMA_SetPeriphBurstxfer(DMA1, LL_DMA_STREAM_0, LL_DMA_PBURST_SINGLE);

  /* SPI1_RX Init */
  LL_DMA_SetPeriphRequest(DMA1, LL_DMA_STREAM_1, LL_DMAMUX1_REQ_SPI1_RX);

  LL_DMA_SetDataTransferDirection(DMA1, LL_DMA_STREAM_1, LL_DMA_DIRECTION_PERIPH_TO_MEMORY);

  LL_DMA_SetStreamPriorityLevel(DMA1, LL_DMA_STREAM_1, LL_DMA_PRIORITY_MEDIUM);

  LL_DMA_SetMode(DMA1, LL_DMA_STREAM_1, LL_DMA_MODE_NORMAL);

  LL_DMA_SetPeriphIncMode(DMA1, LL_DMA_STREAM_1, LL_DMA_PERIPH_NOINCREMENT);

  LL_DMA_SetMemoryIncMode(DMA1, LL_DMA_STREAM_1, LL_DMA_MEMORY_INCREMENT);

  LL_DMA_SetPeriphSize(DMA1, LL_DMA_STREAM_1, LL_DMA_PDATAALIGN_HALFWORD);

  LL_DMA_SetMemorySize(DMA1, LL_DMA_STREAM_1, LL_DMA_MDATAALIGN_HALFWORD);

  LL_DMA_EnableFifoMode(DMA1, LL_DMA_STREAM_1);

  LL_DMA_SetFIFOThreshold(DMA1, LL_DMA_STREAM_1, LL_DMA_FIFOTHRESHOLD_FULL);

  LL_DMA_SetMemoryBurstxfer(DMA1, LL_DMA_STREAM_1, LL_DMA_MBURST_SINGLE);

  LL_DMA_SetPeriphBurstxfer(DMA1, LL_DMA_STREAM_1, LL_DMA_PBURST_SINGLE);

  /* SPI1 interrupt Init */
  NVIC_SetPriority(SPI1_IRQn, NVIC_EncodePriority(NVIC_GetPriorityGrouping(),5, 0));
  NVIC_EnableIRQ(SPI1_IRQn);

  /* SPI1 parameter configuration*/
  SPI_InitStruct.TransferDirection = LL_SPI_FULL_DUPLEX;
  SPI_InitStruct.Mode = LL_SPI_MODE_MASTER;
  SPI_InitStruct.DataWidth = LL_SPI_DATAWIDTH_16BIT;
  SPI_InitStruct.ClockPolarity = LL_SPI_POLARITY_LOW;
  SPI_InitStruct.ClockPhase = LL_SPI_PHASE_1EDGE;
  SPI_InitStruct.NSS = LL_SPI_NSS_HARD_OUTPUT;
  SPI_InitStruct.BaudRate = LL_SPI_BAUDRATEPRESCALER_DIV4;
  SPI_InitStruct.BitOrder = LL_SPI_MSB_FIRST;
  SPI_InitStruct.CRCCalculation = LL_SPI_CRCCALCULATION_DISABLE;
  SPI_InitStruct.CRCPoly = 0x0;
  LL_SPI_Init(SPI1, &SPI_InitStruct);
  LL_SPI_SetStandard(SPI1, LL_SPI_PROTOCOL_MOTOROLA);
  LL_SPI_SetFIFOThreshold(SPI1, LL_SPI_FIFO_TH_04DATA);
  LL_SPI_EnableNSSPulseMgt(SPI1);

}

static void MX_SPI2_Init(void)
{

  /* USER CODE BEGIN SPI2_Init 0 */
	LL_DMA_ConfigAddresses(DMA1, LL_DMA_STREAM_2, (uint32_t) spi2_tx_buffer,
			(uint32_t) &(SPI2->TXDR), LL_DMA_DIRECTION_MEMORY_TO_PERIPH);
	LL_DMA_ConfigAddresses(DMA1, LL_DMA_STREAM_3, (uint32_t) &(SPI2->RXDR),
			(uint32_t) spi2_rx_buffer, LL_DMA_DIRECTION_PERIPH_TO_MEMORY);

  /* USER CODE END SPI2_Init 0 */

  LL_SPI_InitTypeDef SPI_InitStruct = {0};

  LL_GPIO_InitTypeDef GPIO_InitStruct = {0};
  RCC_PeriphCLKInitTypeDef PeriphClkInitStruct = {0};

  /** Initializes the peripherals clock
  */
  PeriphClkInitStruct.PeriphClockSelection = RCC_PERIPHCLK_SPI2;
  PeriphClkInitStruct.Spi123ClockSelection = RCC_SPI123CLKSOURCE_PLL;
  if (HAL_RCCEx_PeriphCLKConfig(&PeriphClkInitStruct) != HAL_OK)
  {
    Error_Handler();
  }

  /* Peripheral clock enable */
  LL_APB1_GRP1_EnableClock(LL_APB1_GRP1_PERIPH_SPI2);

  LL_AHB4_GRP1_EnableClock(LL_AHB4_GRP1_PERIPH_GPIOC);
  LL_AHB4_GRP1_EnableClock(LL_AHB4_GRP1_PERIPH_GPIOB);
  /**SPI2 GPIO Configuration
  PC2_C   ------> SPI2_MISO
  PC3_C   ------> SPI2_MOSI
  PB10   ------> SPI2_SCK
  PB12   ------> SPI2_NSS
  */
  GPIO_InitStruct.Pin = LL_GPIO_PIN_2|LL_GPIO_PIN_3;
  GPIO_InitStruct.Mode = LL_GPIO_MODE_ALTERNATE;
  GPIO_InitStruct.Speed = LL_GPIO_SPEED_FREQ_MEDIUM;
  GPIO_InitStruct.OutputType = LL_GPIO_OUTPUT_PUSHPULL;
  GPIO_InitStruct.Pull = LL_GPIO_PULL_NO;
  GPIO_InitStruct.Alternate = LL_GPIO_AF_5;
  LL_GPIO_Init(GPIOC, &GPIO_InitStruct);

  GPIO_InitStruct.Pin = LL_GPIO_PIN_10|LL_GPIO_PIN_12;
  GPIO_InitStruct.Mode = LL_GPIO_MODE_ALTERNATE;
  GPIO_InitStruct.Speed = LL_GPIO_SPEED_FREQ_MEDIUM;
  GPIO_InitStruct.OutputType = LL_GPIO_OUTPUT_PUSHPULL;
  GPIO_InitStruct.Pull = LL_GPIO_PULL_NO;
  GPIO_InitStruct.Alternate = LL_GPIO_AF_5;
  LL_GPIO_Init(GPIOB, &GPIO_InitStruct);

  /* SPI2 DMA Init */

  /* SPI2_TX Init */
  LL_DMA_SetPeriphRequest(DMA1, LL_DMA_STREAM_2, LL_DMAMUX1_REQ_SPI2_TX);

  LL_DMA_SetDataTransferDirection(DMA1, LL_DMA_STREAM_2, LL_DMA_DIRECTION_MEMORY_TO_PERIPH);

  LL_DMA_SetStreamPriorityLevel(DMA1, LL_DMA_STREAM_2, LL_DMA_PRIORITY_LOW);

  LL_DMA_SetMode(DMA1, LL_DMA_STREAM_2, LL_DMA_MODE_NORMAL);

  LL_DMA_SetPeriphIncMode(DMA1, LL_DMA_STREAM_2, LL_DMA_PERIPH_NOINCREMENT);

  LL_DMA_SetMemoryIncMode(DMA1, LL_DMA_STREAM_2, LL_DMA_MEMORY_INCREMENT);

  LL_DMA_SetPeriphSize(DMA1, LL_DMA_STREAM_2, LL_DMA_PDATAALIGN_HALFWORD);

  LL_DMA_SetMemorySize(DMA1, LL_DMA_STREAM_2, LL_DMA_MDATAALIGN_HALFWORD);

  LL_DMA_EnableFifoMode(DMA1, LL_DMA_STREAM_2);

  LL_DMA_SetFIFOThreshold(DMA1, LL_DMA_STREAM_2, LL_DMA_FIFOTHRESHOLD_FULL);

  LL_DMA_SetMemoryBurstxfer(DMA1, LL_DMA_STREAM_2, LL_DMA_MBURST_SINGLE);

  LL_DMA_SetPeriphBurstxfer(DMA1, LL_DMA_STREAM_2, LL_DMA_PBURST_SINGLE);

  /* SPI2_RX Init */
  LL_DMA_SetPeriphRequest(DMA1, LL_DMA_STREAM_3, LL_DMAMUX1_REQ_SPI2_RX);

  LL_DMA_SetDataTransferDirection(DMA1, LL_DMA_STREAM_3, LL_DMA_DIRECTION_PERIPH_TO_MEMORY);

  LL_DMA_SetStreamPriorityLevel(DMA1, LL_DMA_STREAM_3, LL_DMA_PRIORITY_LOW);

  LL_DMA_SetMode(DMA1, LL_DMA_STREAM_3, LL_DMA_MODE_NORMAL);

  LL_DMA_SetPeriphIncMode(DMA1, LL_DMA_STREAM_3, LL_DMA_PERIPH_NOINCREMENT);

  LL_DMA_SetMemoryIncMode(DMA1, LL_DMA_STREAM_3, LL_DMA_MEMORY_INCREMENT);

  LL_DMA_SetPeriphSize(DMA1, LL_DMA_STREAM_3, LL_DMA_PDATAALIGN_HALFWORD);

  LL_DMA_SetMemorySize(DMA1, LL_DMA_STREAM_3, LL_DMA_MDATAALIGN_HALFWORD);

  LL_DMA_DisableFifoMode(DMA1, LL_DMA_STREAM_3);

  /* SPI2 interrupt Init */
  NVIC_SetPriority(SPI2_IRQn, NVIC_EncodePriority(NVIC_GetPriorityGrouping(),4, 0));
  NVIC_EnableIRQ(SPI2_IRQn);

  /* SPI2 parameter configuration*/
  SPI_InitStruct.TransferDirection = LL_SPI_FULL_DUPLEX;
  SPI_InitStruct.Mode = LL_SPI_MODE_MASTER;
  SPI_InitStruct.DataWidth = LL_SPI_DATAWIDTH_16BIT;
  SPI_InitStruct.ClockPolarity = LL_SPI_POLARITY_LOW;
  SPI_InitStruct.ClockPhase = LL_SPI_PHASE_1EDGE;
  SPI_InitStruct.NSS = LL_SPI_NSS_HARD_OUTPUT;
  SPI_InitStruct.BaudRate = LL_SPI_BAUDRATEPRESCALER_DIV4;
  SPI_InitStruct.BitOrder = LL_SPI_MSB_FIRST;
  SPI_InitStruct.CRCCalculation = LL_SPI_CRCCALCULATION_DISABLE;
  SPI_InitStruct.CRCPoly = 0x0;
  LL_SPI_Init(SPI2, &SPI_InitStruct);
  LL_SPI_SetStandard(SPI2, LL_SPI_PROTOCOL_MOTOROLA);
  LL_SPI_SetFIFOThreshold(SPI2, LL_SPI_FIFO_TH_02DATA);
  LL_SPI_EnableNSSPulseMgt(SPI2);

}

static void MX_SPI3_Init(void)
{

  /* USER CODE BEGIN SPI3_Init 0 */
	LL_DMA_ConfigAddresses(DMA2, LL_DMA_STREAM_0, (uint32_t) spi3_tx_buffer,
			(uint32_t) &(SPI3->TXDR), LL_DMA_DIRECTION_MEMORY_TO_PERIPH);
	LL_DMA_ConfigAddresses(DMA2, LL_DMA_STREAM_1, (uint32_t) &(SPI3->RXDR),
			(uint32_t) spi3_rx_buffer, LL_DMA_DIRECTION_PERIPH_TO_MEMORY);

  /* USER CODE END SPI3_Init 0 */

  LL_SPI_InitTypeDef SPI_InitStruct = {0};

  LL_GPIO_InitTypeDef GPIO_InitStruct = {0};
  RCC_PeriphCLKInitTypeDef PeriphClkInitStruct = {0};

  /** Initializes the peripherals clock
  */
  PeriphClkInitStruct.PeriphClockSelection = RCC_PERIPHCLK_SPI3;
  PeriphClkInitStruct.Spi123ClockSelection = RCC_SPI123CLKSOURCE_PLL;
  if (HAL_RCCEx_PeriphCLKConfig(&PeriphClkInitStruct) != HAL_OK)
  {
    Error_Handler();
  }

  /* Peripheral clock enable */
  LL_APB1_GRP1_EnableClock(LL_APB1_GRP1_PERIPH_SPI3);

  LL_AHB4_GRP1_EnableClock(LL_AHB4_GRP1_PERIPH_GPIOA);
  LL_AHB4_GRP1_EnableClock(LL_AHB4_GRP1_PERIPH_GPIOC);
  /**SPI3 GPIO Configuration
  PA15 (JTDI)   ------> SPI3_NSS
  PC10   ------> SPI3_SCK
  PC11   ------> SPI3_MISO
  PC12   ------> SPI3_MOSI
  */
  GPIO_InitStruct.Pin = LL_GPIO_PIN_15;
  GPIO_InitStruct.Mode = LL_GPIO_MODE_ALTERNATE;
  GPIO_InitStruct.Speed = LL_GPIO_SPEED_FREQ_MEDIUM;
  GPIO_InitStruct.OutputType = LL_GPIO_OUTPUT_PUSHPULL;
  GPIO_InitStruct.Pull = LL_GPIO_PULL_NO;
  GPIO_InitStruct.Alternate = LL_GPIO_AF_6;
  LL_GPIO_Init(GPIOA, &GPIO_InitStruct);

  GPIO_InitStruct.Pin = LL_GPIO_PIN_10|LL_GPIO_PIN_11|LL_GPIO_PIN_12;
  GPIO_InitStruct.Mode = LL_GPIO_MODE_ALTERNATE;
  GPIO_InitStruct.Speed = LL_GPIO_SPEED_FREQ_MEDIUM;
  GPIO_InitStruct.OutputType = LL_GPIO_OUTPUT_PUSHPULL;
  GPIO_InitStruct.Pull = LL_GPIO_PULL_NO;
  GPIO_InitStruct.Alternate = LL_GPIO_AF_6;
  LL_GPIO_Init(GPIOC, &GPIO_InitStruct);

  /* SPI3 DMA Init */

  /* SPI3_TX Init */
  LL_DMA_SetPeriphRequest(DMA2, LL_DMA_STREAM_0, LL_DMAMUX1_REQ_SPI3_TX);

  LL_DMA_SetDataTransferDirection(DMA2, LL_DMA_STREAM_0, LL_DMA_DIRECTION_MEMORY_TO_PERIPH);

  LL_DMA_SetStreamPriorityLevel(DMA2, LL_DMA_STREAM_0, LL_DMA_PRIORITY_LOW);

  LL_DMA_SetMode(DMA2, LL_DMA_STREAM_0, LL_DMA_MODE_NORMAL);

  LL_DMA_SetPeriphIncMode(DMA2, LL_DMA_STREAM_0, LL_DMA_PERIPH_NOINCREMENT);

  LL_DMA_SetMemoryIncMode(DMA2, LL_DMA_STREAM_0, LL_DMA_MEMORY_INCREMENT);

  LL_DMA_SetPeriphSize(DMA2, LL_DMA_STREAM_0, LL_DMA_PDATAALIGN_HALFWORD);

  LL_DMA_SetMemorySize(DMA2, LL_DMA_STREAM_0, LL_DMA_MDATAALIGN_HALFWORD);

  LL_DMA_EnableFifoMode(DMA2, LL_DMA_STREAM_0);

  LL_DMA_SetFIFOThreshold(DMA2, LL_DMA_STREAM_0, LL_DMA_FIFOTHRESHOLD_FULL);

  LL_DMA_SetMemoryBurstxfer(DMA2, LL_DMA_STREAM_0, LL_DMA_MBURST_SINGLE);

  LL_DMA_SetPeriphBurstxfer(DMA2, LL_DMA_STREAM_0, LL_DMA_PBURST_SINGLE);

  /* SPI3_RX Init */
  LL_DMA_SetPeriphRequest(DMA2, LL_DMA_STREAM_1, LL_DMAMUX1_REQ_SPI3_RX);

  LL_DMA_SetDataTransferDirection(DMA2, LL_DMA_STREAM_1, LL_DMA_DIRECTION_PERIPH_TO_MEMORY);

  LL_DMA_SetStreamPriorityLevel(DMA2, LL_DMA_STREAM_1, LL_DMA_PRIORITY_LOW);

  LL_DMA_SetMode(DMA2, LL_DMA_STREAM_1, LL_DMA_MODE_NORMAL);

  LL_DMA_SetPeriphIncMode(DMA2, LL_DMA_STREAM_1, LL_DMA_PERIPH_NOINCREMENT);

  LL_DMA_SetMemoryIncMode(DMA2, LL_DMA_STREAM_1, LL_DMA_MEMORY_INCREMENT);

  LL_DMA_SetPeriphSize(DMA2, LL_DMA_STREAM_1, LL_DMA_PDATAALIGN_HALFWORD);

  LL_DMA_SetMemorySize(DMA2, LL_DMA_STREAM_1, LL_DMA_MDATAALIGN_HALFWORD);

  LL_DMA_EnableFifoMode(DMA2, LL_DMA_STREAM_1);

  LL_DMA_SetFIFOThreshold(DMA2, LL_DMA_STREAM_1, LL_DMA_FIFOTHRESHOLD_FULL);

  LL_DMA_SetMemoryBurstxfer(DMA2, LL_DMA_STREAM_1, LL_DMA_MBURST_SINGLE);

  LL_DMA_SetPeriphBurstxfer(DMA2, LL_DMA_STREAM_1, LL_DMA_PBURST_SINGLE);

  /* SPI3 interrupt Init */
  NVIC_SetPriority(SPI3_IRQn, NVIC_EncodePriority(NVIC_GetPriorityGrouping(),3, 0));
  NVIC_EnableIRQ(SPI3_IRQn);

  /* SPI3 parameter configuration*/
  SPI_InitStruct.TransferDirection = LL_SPI_FULL_DUPLEX;
  SPI_InitStruct.Mode = LL_SPI_MODE_MASTER;
  SPI_InitStruct.DataWidth = LL_SPI_DATAWIDTH_16BIT;
  SPI_InitStruct.ClockPolarity = LL_SPI_POLARITY_LOW;
  SPI_InitStruct.ClockPhase = LL_SPI_PHASE_1EDGE;
  SPI_InitStruct.NSS = LL_SPI_NSS_HARD_OUTPUT;
  SPI_InitStruct.BaudRate = LL_SPI_BAUDRATEPRESCALER_DIV4;
  SPI_InitStruct.BitOrder = LL_SPI_MSB_FIRST;
  SPI_InitStruct.CRCCalculation = LL_SPI_CRCCALCULATION_DISABLE;
  SPI_InitStruct.CRCPoly = 0x0;
  LL_SPI_Init(SPI3, &SPI_InitStruct);
  LL_SPI_SetStandard(SPI3, LL_SPI_PROTOCOL_MOTOROLA);
  LL_SPI_SetFIFOThreshold(SPI3, LL_SPI_FIFO_TH_01DATA);
  LL_SPI_EnableNSSPulseMgt(SPI3);

}

static void MX_SPI4_Init(void)
{

  /* USER CODE BEGIN SPI4_Init 0 */
	LL_DMA_ConfigAddresses(DMA2, LL_DMA_STREAM_2, (uint32_t) spi4_tx_buffer,
			(uint32_t) &(SPI4->TXDR), LL_DMA_DIRECTION_MEMORY_TO_PERIPH);
	LL_DMA_ConfigAddresses(DMA2, LL_DMA_STREAM_3, (uint32_t) &(SPI4->RXDR),
			(uint32_t) spi4_rx_buffer, LL_DMA_DIRECTION_PERIPH_TO_MEMORY);

  /* USER CODE END SPI4_Init 0 */

  LL_SPI_InitTypeDef SPI_InitStruct = {0};

  LL_GPIO_InitTypeDef GPIO_InitStruct = {0};
  RCC_PeriphCLKInitTypeDef PeriphClkInitStruct = {0};

  /** Initializes the peripherals clock
  */
  PeriphClkInitStruct.PeriphClockSelection = RCC_PERIPHCLK_SPI4;
  PeriphClkInitStruct.PLL2.PLL2M = 4;
  PeriphClkInitStruct.PLL2.PLL2N = 30;
  PeriphClkInitStruct.PLL2.PLL2P = 2;
  PeriphClkInitStruct.PLL2.PLL2Q = 4;
  PeriphClkInitStruct.PLL2.PLL2R = 2;
  PeriphClkInitStruct.PLL2.PLL2RGE = RCC_PLL2VCIRANGE_3;
  PeriphClkInitStruct.PLL2.PLL2VCOSEL = RCC_PLL2VCOWIDE;
  PeriphClkInitStruct.PLL2.PLL2FRACN = 0;
  PeriphClkInitStruct.Spi45ClockSelection = RCC_SPI45CLKSOURCE_PLL2;
  if (HAL_RCCEx_PeriphCLKConfig(&PeriphClkInitStruct) != HAL_OK)
  {
    Error_Handler();
  }

  /* Peripheral clock enable */
  LL_APB2_GRP1_EnableClock(LL_APB2_GRP1_PERIPH_SPI4);

  LL_AHB4_GRP1_EnableClock(LL_AHB4_GRP1_PERIPH_GPIOE);
  /**SPI4 GPIO Configuration
  PE2   ------> SPI4_SCK
  PE4   ------> SPI4_NSS
  PE5   ------> SPI4_MISO
  PE6   ------> SPI4_MOSI
  */
  GPIO_InitStruct.Pin = LL_GPIO_PIN_2|LL_GPIO_PIN_4|LL_GPIO_PIN_5|LL_GPIO_PIN_6;
  GPIO_InitStruct.Mode = LL_GPIO_MODE_ALTERNATE;
  GPIO_InitStruct.Speed = LL_GPIO_SPEED_FREQ_MEDIUM;
  GPIO_InitStruct.OutputType = LL_GPIO_OUTPUT_PUSHPULL;
  GPIO_InitStruct.Pull = LL_GPIO_PULL_NO;
  GPIO_InitStruct.Alternate = LL_GPIO_AF_5;
  LL_GPIO_Init(GPIOE, &GPIO_InitStruct);

  /* SPI4 DMA Init */

  /* SPI4_TX Init */
  LL_DMA_SetPeriphRequest(DMA2, LL_DMA_STREAM_2, LL_DMAMUX1_REQ_SPI4_TX);

  LL_DMA_SetDataTransferDirection(DMA2, LL_DMA_STREAM_2, LL_DMA_DIRECTION_MEMORY_TO_PERIPH);

  LL_DMA_SetStreamPriorityLevel(DMA2, LL_DMA_STREAM_2, LL_DMA_PRIORITY_LOW);

  LL_DMA_SetMode(DMA2, LL_DMA_STREAM_2, LL_DMA_MODE_NORMAL);

  LL_DMA_SetPeriphIncMode(DMA2, LL_DMA_STREAM_2, LL_DMA_PERIPH_NOINCREMENT);

  LL_DMA_SetMemoryIncMode(DMA2, LL_DMA_STREAM_2, LL_DMA_MEMORY_INCREMENT);

  LL_DMA_SetPeriphSize(DMA2, LL_DMA_STREAM_2, LL_DMA_PDATAALIGN_HALFWORD);

  LL_DMA_SetMemorySize(DMA2, LL_DMA_STREAM_2, LL_DMA_MDATAALIGN_HALFWORD);

  LL_DMA_EnableFifoMode(DMA2, LL_DMA_STREAM_2);

  LL_DMA_SetFIFOThreshold(DMA2, LL_DMA_STREAM_2, LL_DMA_FIFOTHRESHOLD_FULL);

  LL_DMA_SetMemoryBurstxfer(DMA2, LL_DMA_STREAM_2, LL_DMA_MBURST_SINGLE);

  LL_DMA_SetPeriphBurstxfer(DMA2, LL_DMA_STREAM_2, LL_DMA_PBURST_SINGLE);

  /* SPI4_RX Init */
  LL_DMA_SetPeriphRequest(DMA2, LL_DMA_STREAM_3, LL_DMAMUX1_REQ_SPI4_RX);

  LL_DMA_SetDataTransferDirection(DMA2, LL_DMA_STREAM_3, LL_DMA_DIRECTION_PERIPH_TO_MEMORY);

  LL_DMA_SetStreamPriorityLevel(DMA2, LL_DMA_STREAM_3, LL_DMA_PRIORITY_LOW);

  LL_DMA_SetMode(DMA2, LL_DMA_STREAM_3, LL_DMA_MODE_NORMAL);

  LL_DMA_SetPeriphIncMode(DMA2, LL_DMA_STREAM_3, LL_DMA_PERIPH_NOINCREMENT);

  LL_DMA_SetMemoryIncMode(DMA2, LL_DMA_STREAM_3, LL_DMA_MEMORY_INCREMENT);

  LL_DMA_SetPeriphSize(DMA2, LL_DMA_STREAM_3, LL_DMA_PDATAALIGN_HALFWORD);

  LL_DMA_SetMemorySize(DMA2, LL_DMA_STREAM_3, LL_DMA_MDATAALIGN_HALFWORD);

  LL_DMA_EnableFifoMode(DMA2, LL_DMA_STREAM_3);

  LL_DMA_SetFIFOThreshold(DMA2, LL_DMA_STREAM_3, LL_DMA_FIFOTHRESHOLD_FULL);

  LL_DMA_SetMemoryBurstxfer(DMA2, LL_DMA_STREAM_3, LL_DMA_MBURST_SINGLE);

  LL_DMA_SetPeriphBurstxfer(DMA2, LL_DMA_STREAM_3, LL_DMA_PBURST_SINGLE);

  /* SPI4 interrupt Init */
  NVIC_SetPriority(SPI4_IRQn, NVIC_EncodePriority(NVIC_GetPriorityGrouping(),2, 0));
  NVIC_EnableIRQ(SPI4_IRQn);

  /* SPI4 parameter configuration*/
  SPI_InitStruct.TransferDirection = LL_SPI_FULL_DUPLEX;
  SPI_InitStruct.Mode = LL_SPI_MODE_MASTER;
  SPI_InitStruct.DataWidth = LL_SPI_DATAWIDTH_16BIT;
  SPI_InitStruct.ClockPolarity = LL_SPI_POLARITY_LOW;
  SPI_InitStruct.ClockPhase = LL_SPI_PHASE_1EDGE;
  SPI_InitStruct.NSS = LL_SPI_NSS_HARD_OUTPUT;
  SPI_InitStruct.BaudRate = LL_SPI_BAUDRATEPRESCALER_DIV4;
  SPI_InitStruct.BitOrder = LL_SPI_MSB_FIRST;
  SPI_InitStruct.CRCCalculation = LL_SPI_CRCCALCULATION_DISABLE;
  SPI_InitStruct.CRCPoly = 0x0;
  LL_SPI_Init(SPI4, &SPI_InitStruct);
  LL_SPI_SetStandard(SPI4, LL_SPI_PROTOCOL_MOTOROLA);
  LL_SPI_SetFIFOThreshold(SPI4, LL_SPI_FIFO_TH_01DATA);
  LL_SPI_EnableNSSPulseMgt(SPI4);

}

static void MX_TIM2_Init(void)
{

  TIM_ClockConfigTypeDef sClockSourceConfig = {0};
  TIM_MasterConfigTypeDef sMasterConfig = {0};

  htim2.Instance = TIM2;
  htim2.Init.Prescaler = 0;
  htim2.Init.CounterMode = TIM_COUNTERMODE_UP;
  htim2.Init.Period = 240000-1;
  htim2.Init.ClockDivision = TIM_CLOCKDIVISION_DIV1;
  htim2.Init.AutoReloadPreload = TIM_AUTORELOAD_PRELOAD_DISABLE;
  if (HAL_TIM_Base_Init(&htim2) != HAL_OK)
  {
    Error_Handler();
  }
  sClockSourceConfig.ClockSource = TIM_CLOCKSOURCE_INTERNAL;
  if (HAL_TIM_ConfigClockSource(&htim2, &sClockSourceConfig) != HAL_OK)
  {
    Error_Handler();
  }
  sMasterConfig.MasterOutputTrigger = TIM_TRGO_RESET;
  sMasterConfig.MasterSlaveMode = TIM_MASTERSLAVEMODE_DISABLE;
  if (HAL_TIMEx_MasterConfigSynchronization(&htim2, &sMasterConfig) != HAL_OK)
  {
    Error_Handler();
  }

}

static void MX_USART3_UART_Init(void)
{

  huart3.Instance = USART3;
  huart3.Init.BaudRate = 115200;
  huart3.Init.WordLength = UART_WORDLENGTH_8B;
  huart3.Init.StopBits = UART_STOPBITS_1;
  huart3.Init.Parity = UART_PARITY_NONE;
  huart3.Init.Mode = UART_MODE_TX_RX;
  huart3.Init.HwFlowCtl = UART_HWCONTROL_NONE;
  huart3.Init.OverSampling = UART_OVERSAMPLING_16;
  huart3.Init.OneBitSampling = UART_ONE_BIT_SAMPLE_DISABLE;
  huart3.Init.ClockPrescaler = UART_PRESCALER_DIV1;
  huart3.AdvancedInit.AdvFeatureInit = UART_ADVFEATURE_NO_INIT;
  if (HAL_UART_Init(&huart3) != HAL_OK)
  {
    Error_Handler();
  }
  if (HAL_UARTEx_SetTxFifoThreshold(&huart3, UART_TXFIFO_THRESHOLD_1_8) != HAL_OK)
  {
    Error_Handler();
  }
  if (HAL_UARTEx_SetRxFifoThreshold(&huart3, UART_RXFIFO_THRESHOLD_1_8) != HAL_OK)
  {
    Error_Handler();
  }
  if (HAL_UARTEx_DisableFifoMode(&huart3) != HAL_OK)
  {
    Error_Handler();
  }

}

static void MX_DMA_Init(void)
{

  /* DMA controller clock enable */
  __HAL_RCC_DMA1_CLK_ENABLE();
  __HAL_RCC_DMA2_CLK_ENABLE();

  /* DMA interrupt init */
  /* DMA1_Stream0_IRQn interrupt configuration */
  NVIC_SetPriority(DMA1_Stream0_IRQn, NVIC_EncodePriority(NVIC_GetPriorityGrouping(),0, 0));
  NVIC_EnableIRQ(DMA1_Stream0_IRQn);
  /* DMA1_Stream1_IRQn interrupt configuration */
  NVIC_SetPriority(DMA1_Stream1_IRQn, NVIC_EncodePriority(NVIC_GetPriorityGrouping(),0, 0));
  NVIC_EnableIRQ(DMA1_Stream1_IRQn);
  /* DMA1_Stream2_IRQn interrupt configuration */
  NVIC_SetPriority(DMA1_Stream2_IRQn, NVIC_EncodePriority(NVIC_GetPriorityGrouping(),0, 0));
  NVIC_EnableIRQ(DMA1_Stream2_IRQn);
  /* DMA1_Stream3_IRQn interrupt configuration */
  NVIC_SetPriority(DMA1_Stream3_IRQn, NVIC_EncodePriority(NVIC_GetPriorityGrouping(),0, 0));
  NVIC_EnableIRQ(DMA1_Stream3_IRQn);
  /* DMA2_Stream0_IRQn interrupt configuration */
  NVIC_SetPriority(DMA2_Stream0_IRQn, NVIC_EncodePriority(NVIC_GetPriorityGrouping(),0, 0));
  NVIC_EnableIRQ(DMA2_Stream0_IRQn);
  /* DMA2_Stream1_IRQn interrupt configuration */
  NVIC_SetPriority(DMA2_Stream1_IRQn, NVIC_EncodePriority(NVIC_GetPriorityGrouping(),0, 0));
  NVIC_EnableIRQ(DMA2_Stream1_IRQn);
  /* DMA2_Stream2_IRQn interrupt configuration */
  NVIC_SetPriority(DMA2_Stream2_IRQn, NVIC_EncodePriority(NVIC_GetPriorityGrouping(),0, 0));
  NVIC_EnableIRQ(DMA2_Stream2_IRQn);
  /* DMA2_Stream3_IRQn interrupt configuration */
  NVIC_SetPriority(DMA2_Stream3_IRQn, NVIC_EncodePriority(NVIC_GetPriorityGrouping(),0, 0));
  NVIC_EnableIRQ(DMA2_Stream3_IRQn);

}

static void MX_GPIO_Init(void)
{
  GPIO_InitTypeDef GPIO_InitStruct = {0};

  /* GPIO Ports Clock Enable */
  __HAL_RCC_GPIOE_CLK_ENABLE();
  __HAL_RCC_GPIOC_CLK_ENABLE();
  __HAL_RCC_GPIOH_CLK_ENABLE();
  __HAL_RCC_GPIOA_CLK_ENABLE();
  __HAL_RCC_GPIOB_CLK_ENABLE();
  __HAL_RCC_GPIOD_CLK_ENABLE();
  __HAL_RCC_GPIOG_CLK_ENABLE();

  /*Configure GPIO pin Output Level */
  HAL_GPIO_WritePin(LED0_GPIO_Port, LED0_Pin, GPIO_PIN_RESET);

  /*Configure GPIO pin : LED0_Pin */
  GPIO_InitStruct.Pin = LED0_Pin;
  GPIO_InitStruct.Mode = GPIO_MODE_OUTPUT_PP;
  GPIO_InitStruct.Pull = GPIO_NOPULL;
  GPIO_InitStruct.Speed = GPIO_SPEED_FREQ_LOW;
  HAL_GPIO_Init(LED0_GPIO_Port, &GPIO_InitStruct);

}

/* USER CODE BEGIN 4 */

void DWT_Init(void){
	CoreDebug->DEMCR |= CoreDebug_DEMCR_TRCENA_Msk;
	DWT->CYCCNT = 0;
	DWT->CTRL |= DWT_CTRL_CYCCNTENA_Msk;

}

void udp_receive_callback(void *arg, // User argument - udp_recv `arg` parameter
		struct udp_pcb *upcb,   // Receiving Protocol Control Block
		struct pbuf *p,         // Pointer to Datagram
		const ip_addr_t *addr,  // Address of sender
		u16_t port) {

	start_time = get_sys_time();
	TIM2->CNT=0; // reset timer
//	char msg[100];
//	sprintf(msg, "start: %lu\r\n", start_time_us);
//	print_uart3(msg);
	// get sender ip address and port information
	ip_addr_copy(client_addr, *addr);
	client_port = port;
	// process the data
	uint16_t udp_size = p->len;
	memcpy(udp_rx.bytes, p->payload, udp_size);

	/* data are big endian and need to be converted to little endian */
	int size = udp_size / 2;
	for (int i = 0; i < size; i++) {
		udp_rx.values[i] = __builtin_bswap16(udp_rx.values[i]);
	}
	test_val = udp_rx.values[0];

	/* handle data here and distribute to individual SPI channels */
	memcpy(spi1_tx_buffer, udp_rx.values, udp_size);
	memcpy(spi2_tx_buffer, udp_rx.values, udp_size);
	memcpy(spi3_tx_buffer, udp_rx.values, udp_size);
	memcpy(spi4_tx_buffer, udp_rx.values, udp_size);

	// signal main to initiate SPI transfer
	spi_data_ready = 1;

	pbuf_free(p);
}

split_time_t get_sys_time(void) {
	split_time_t current;

	current.us = (TIM2->CNT);
	current.ms = sys_time_ms;
	current.us /=240;
	return (current); // current time in millseconds

}

/**************************************************************/

void SPI1_DMA_txfer(void) {
	// 1. Clear ALL relevant SPI flags (EOT, TXTF, and Errors)
	// If any error flags are set, the SPI might refuse to start CSTART
	LL_SPI_ClearFlag_EOT(SPI1);
	LL_SPI_ClearFlag_TXTF(SPI1);
	LL_SPI_ClearFlag_OVR(SPI1);
	LL_SPI_ClearFlag_UDR(SPI1);

	// 2. Cache Maintenance
	SCB_CleanDCache_by_Addr((uint32_t*) spi1_tx_buffer, SPI_BUFFER_SIZE_BYTES);

	// 3. Ensure both DMA streams are fully disabled before reconfiguration
	LL_DMA_DisableStream(DMA1, LL_DMA_STREAM_0);
	LL_DMA_DisableStream(DMA1, LL_DMA_STREAM_1);
	while (LL_DMA_IsEnabledStream(DMA1, LL_DMA_STREAM_0))
		;
	while (LL_DMA_IsEnabledStream(DMA1, LL_DMA_STREAM_1))
		;

	// 4. Clear DMA Interrupt Flags
	LL_DMA_ClearFlag_TC0(DMA1); // TX Stream
	LL_DMA_ClearFlag_TC1(DMA1); // RX Stream

	// 5. Re-set lengths
	LL_DMA_SetDataLength(DMA1, LL_DMA_STREAM_0, NUM_ACTUATORS);
	LL_DMA_SetDataLength(DMA1, LL_DMA_STREAM_1, NUM_ACTUATORS);

	// 6. Enable DMA Streams (RX FIRST!)
	LL_DMA_EnableStream(DMA1, LL_DMA_STREAM_1);
	LL_DMA_EnableStream(DMA1, LL_DMA_STREAM_0);

	// 7. SPI Configuration & Start
	LL_SPI_SetTransferSize(SPI1, NUM_ACTUATORS);

	// Enable the transfer complete IRQ
	LL_DMA_EnableIT_TC(DMA1, LL_DMA_STREAM_1);

	// CRITICAL: Ensure DMA Requests are enabled in the SPI peripheral
	LL_SPI_EnableDMAReq_RX(SPI1);
	LL_SPI_EnableDMAReq_TX(SPI1);

	if (!LL_SPI_IsEnabled(SPI1)) {
		// Add this right before LL_SPI_Enable(...)
		while (LL_SPI_IsActiveFlag_RXP(SPI1)) {
			(void) LL_SPI_ReceiveData16(SPI1); // Read and discard
		}
		LL_SPI_Enable(SPI1);
	}
	// Trigger the transaction
	LL_SPI_StartMasterTransfer(SPI1);
}

void SPI2_DMA_txfer(void) {
	// 1. Clear ALL relevant SPI flags (EOT, TXTF, and Errors)
	// If any error flags are set, the SPI might refuse to start CSTART
	LL_SPI_ClearFlag_EOT(SPI2);
	LL_SPI_ClearFlag_TXTF(SPI2);
	LL_SPI_ClearFlag_OVR(SPI2);
	LL_SPI_ClearFlag_UDR(SPI2);

	// 2. Cache Maintenance
	SCB_CleanDCache_by_Addr((uint32_t*) spi2_tx_buffer, SPI_BUFFER_SIZE_BYTES);

	// 3. Ensure both DMA streams are fully disabled before reconfiguration
	LL_DMA_DisableStream(DMA1, LL_DMA_STREAM_2);
	LL_DMA_DisableStream(DMA1, LL_DMA_STREAM_3);
	while (LL_DMA_IsEnabledStream(DMA1, LL_DMA_STREAM_2))
		;
	while (LL_DMA_IsEnabledStream(DMA1, LL_DMA_STREAM_3))
		;

	// 4. Clear DMA Interrupt Flags
	LL_DMA_ClearFlag_TC2(DMA1); // TX Stream
	LL_DMA_ClearFlag_TC3(DMA1); // RX Stream

	// 5. Re-set lengths
	LL_DMA_SetDataLength(DMA1, LL_DMA_STREAM_2, NUM_ACTUATORS);
	LL_DMA_SetDataLength(DMA1, LL_DMA_STREAM_3, NUM_ACTUATORS);

	// 6. Enable DMA Streams (RX FIRST!)
	LL_DMA_EnableStream(DMA1, LL_DMA_STREAM_2);
	LL_DMA_EnableStream(DMA1, LL_DMA_STREAM_3);

	// 7. SPI Configuration & Start
	LL_SPI_SetTransferSize(SPI2, NUM_ACTUATORS);

	// Enable the transfer complete IRQ
	LL_DMA_EnableIT_TC(DMA1, LL_DMA_STREAM_3);

	// CRITICAL: Ensure DMA Requests are enabled in the SPI peripheral
	LL_SPI_EnableDMAReq_RX(SPI2);
	LL_SPI_EnableDMAReq_TX(SPI2);

	if (!LL_SPI_IsEnabled(SPI2)) {
		// Add this right before LL_SPI_Enable(...)
		while (LL_SPI_IsActiveFlag_RXP(SPI2)) {
			(void) LL_SPI_ReceiveData16(SPI2); // Read and discard
		}
		LL_SPI_Enable(SPI2);
	}
	// Trigger the transaction
	LL_SPI_StartMasterTransfer(SPI2);
}

void SPI3_DMA_txfer(void) {
	// 1. Clear ALL relevant SPI flags (EOT, TXTF, and Errors)
	// If any error flags are set, the SPI might refuse to start CSTART
	LL_SPI_ClearFlag_EOT(SPI3);
	LL_SPI_ClearFlag_TXTF(SPI3);
	LL_SPI_ClearFlag_OVR(SPI3);
	LL_SPI_ClearFlag_UDR(SPI3);

	// 2. Cache Maintenance
	SCB_CleanDCache_by_Addr((uint32_t*) spi3_tx_buffer, SPI_BUFFER_SIZE_BYTES);

	// 3. Ensure both DMA streams are fully disabled before reconfiguration
	LL_DMA_DisableStream(DMA2, LL_DMA_STREAM_0);
	LL_DMA_DisableStream(DMA2, LL_DMA_STREAM_1);
	while (LL_DMA_IsEnabledStream(DMA2, LL_DMA_STREAM_0))
		;
	while (LL_DMA_IsEnabledStream(DMA2, LL_DMA_STREAM_1))
		;

	// 4. Clear DMA Interrupt Flags
	LL_DMA_ClearFlag_TC0(DMA2); // TX Stream
	LL_DMA_ClearFlag_TC1(DMA2); // RX Stream

	// 5. Re-set lengths
	LL_DMA_SetDataLength(DMA2, LL_DMA_STREAM_0, NUM_ACTUATORS);
	LL_DMA_SetDataLength(DMA2, LL_DMA_STREAM_1, NUM_ACTUATORS);

	// 6. Enable DMA Streams
	LL_DMA_EnableStream(DMA2, LL_DMA_STREAM_0);
	LL_DMA_EnableStream(DMA2, LL_DMA_STREAM_1);

	// 7. SPI Configuration & Start
	LL_SPI_SetTransferSize(SPI3, NUM_ACTUATORS);

	// Enable the transfer complete IRQ
	LL_DMA_EnableIT_TC(DMA2, LL_DMA_STREAM_1);

	// CRITICAL: Ensure DMA Requests are enabled in the SPI peripheral
	LL_SPI_EnableDMAReq_RX(SPI3);
	LL_SPI_EnableDMAReq_TX(SPI3);

	if (!LL_SPI_IsEnabled(SPI3)) {
		// Add this right before LL_SPI_Enable(...)
		while (LL_SPI_IsActiveFlag_RXP(SPI3)) {
			(void) LL_SPI_ReceiveData16(SPI3); // Read and discard
		}
		LL_SPI_Enable(SPI3);
	}
	// Trigger the transaction
	LL_SPI_StartMasterTransfer(SPI3);
}

void SPI4_DMA_txfer(void) {
	// 1. Clear ALL relevant SPI flags (EOT, TXTF, and Errors)
	// If any error flags are set, the SPI might refuse to start CSTART
	LL_SPI_ClearFlag_EOT(SPI4);
	LL_SPI_ClearFlag_TXTF(SPI4);
	LL_SPI_ClearFlag_OVR(SPI4);
	LL_SPI_ClearFlag_UDR(SPI4);

	// 2. Cache Maintenance
	SCB_CleanDCache_by_Addr((uint32_t*) spi4_tx_buffer, SPI_BUFFER_SIZE_BYTES);

	// 3. Ensure both DMA streams are fully disabled before reconfiguration
	LL_DMA_DisableStream(DMA2, LL_DMA_STREAM_2);
	LL_DMA_DisableStream(DMA2, LL_DMA_STREAM_3);
	while (LL_DMA_IsEnabledStream(DMA2, LL_DMA_STREAM_2))
		;
	while (LL_DMA_IsEnabledStream(DMA2, LL_DMA_STREAM_3))
		;

	// 4. Clear DMA Interrupt Flags
	LL_DMA_ClearFlag_TC2(DMA2); // TX Stream
	LL_DMA_ClearFlag_TC3(DMA2); // RX Stream

	// 5. Re-set lengths
	LL_DMA_SetDataLength(DMA2, LL_DMA_STREAM_2, NUM_ACTUATORS);
	LL_DMA_SetDataLength(DMA2, LL_DMA_STREAM_3, NUM_ACTUATORS);

	// 6. Enable DMA Streams
	LL_DMA_EnableStream(DMA2, LL_DMA_STREAM_2);
	LL_DMA_EnableStream(DMA2, LL_DMA_STREAM_3);

	// 7. SPI Configuration & Start
	LL_SPI_SetTransferSize(SPI4, NUM_ACTUATORS);

	// Enable the transfer complete IRQ
	LL_DMA_EnableIT_TC(DMA2, LL_DMA_STREAM_3);

	// CRITICAL: Ensure DMA Requests are enabled in the SPI peripheral
	LL_SPI_EnableDMAReq_RX(SPI4);
	LL_SPI_EnableDMAReq_TX(SPI4);

	if (!LL_SPI_IsEnabled(SPI4)) {
		// Add this right before LL_SPI_Enable(...)
		while (LL_SPI_IsActiveFlag_RXP(SPI4)) {
			(void) LL_SPI_ReceiveData16(SPI4); // Read and discard
		}
		LL_SPI_Enable(SPI4);
	}
	// Trigger the transaction
	LL_SPI_StartMasterTransfer(SPI4);
}
/* USER CODE END 4 */

 /* MPU Configuration */

void MPU_Config(void)
{
  MPU_Region_InitTypeDef MPU_InitStruct = {0};

  /* Disables the MPU */
  HAL_MPU_Disable();

  /** Initializes and configures the Region and the memory to be protected
  */
  MPU_InitStruct.Enable = MPU_REGION_ENABLE;
  MPU_InitStruct.Number = MPU_REGION_NUMBER0;
  MPU_InitStruct.BaseAddress = 0x0;
  MPU_InitStruct.Size = MPU_REGION_SIZE_4GB;
  MPU_InitStruct.SubRegionDisable = 0x87;
  MPU_InitStruct.TypeExtField = MPU_TEX_LEVEL0;
  MPU_InitStruct.AccessPermission = MPU_REGION_NO_ACCESS;
  MPU_InitStruct.DisableExec = MPU_INSTRUCTION_ACCESS_DISABLE;
  MPU_InitStruct.IsShareable = MPU_ACCESS_SHAREABLE;
  MPU_InitStruct.IsCacheable = MPU_ACCESS_NOT_CACHEABLE;
  MPU_InitStruct.IsBufferable = MPU_ACCESS_NOT_BUFFERABLE;

  HAL_MPU_ConfigRegion(&MPU_InitStruct);

  /** Initializes and configures the Region and the memory to be protected
  */
  MPU_InitStruct.Number = MPU_REGION_NUMBER1;
  MPU_InitStruct.BaseAddress = 0x30020000;
  MPU_InitStruct.Size = MPU_REGION_SIZE_128KB;
  MPU_InitStruct.SubRegionDisable = 0x0;
  MPU_InitStruct.TypeExtField = MPU_TEX_LEVEL1;
  MPU_InitStruct.AccessPermission = MPU_REGION_FULL_ACCESS;
  MPU_InitStruct.IsShareable = MPU_ACCESS_NOT_SHAREABLE;

  HAL_MPU_ConfigRegion(&MPU_InitStruct);

  /** Initializes and configures the Region and the memory to be protected
  */
  MPU_InitStruct.Number = MPU_REGION_NUMBER2;
  MPU_InitStruct.BaseAddress = 0x30040000;
  MPU_InitStruct.Size = MPU_REGION_SIZE_512B;
  MPU_InitStruct.TypeExtField = MPU_TEX_LEVEL0;
  MPU_InitStruct.IsShareable = MPU_ACCESS_SHAREABLE;
  MPU_InitStruct.IsBufferable = MPU_ACCESS_BUFFERABLE;

  HAL_MPU_ConfigRegion(&MPU_InitStruct);
  /* Enables the MPU */
  HAL_MPU_Enable(MPU_PRIVILEGED_DEFAULT);

}

void HAL_TIM_PeriodElapsedCallback(TIM_HandleTypeDef *htim)
{
  if (htim->Instance == TIM6)
  {
    HAL_IncTick();
  }
}

void Error_Handler(void)
{
	__disable_irq();
	while (1) {
	}
}
